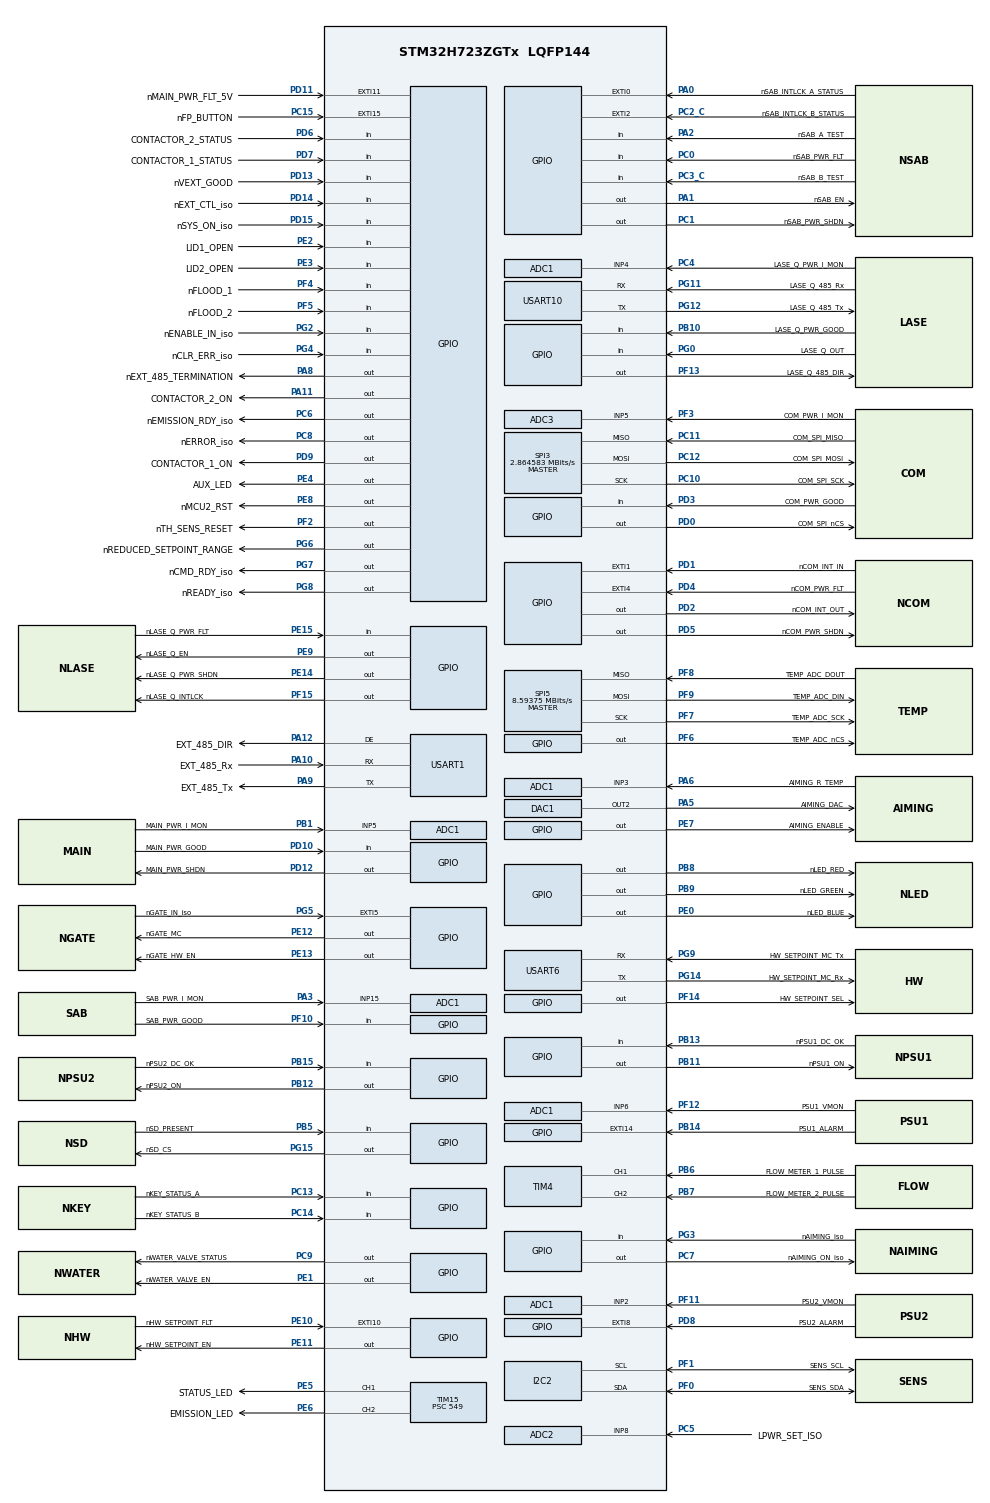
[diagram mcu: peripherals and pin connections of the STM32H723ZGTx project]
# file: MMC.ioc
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ADC1.Channel-0\#ChannelRegularConversion=ADC_CHANNEL_15
ADC1.ClockPrescaler=ADC_CLOCK_ASYNC_DIV2
ADC1.NbrOfConversionFlag=1
ADC1.OffsetNumber-0\#ChannelRegularConversion=ADC_OFFSET_NONE
ADC1.OffsetSignedSaturation-0\#ChannelRegularConversion=DISABLE
ADC1.Rank-0\#ChannelRegularConversion=1
ADC1.Resolution=ADC_RESOLUTION_12B
ADC1.SamplingTime-0\#ChannelRegularConversion=ADC_SAMPLETIME_1CYCLE_5
ADC1.master=1
ADC2.Channel-0\#ChannelRegularConversion=ADC_CHANNEL_8
ADC2.ClockPrescaler=ADC_CLOCK_ASYNC_DIV2
ADC2.NbrOfConversionFlag=1
ADC2.OffsetNumber-0\#ChannelRegularConversion=ADC_OFFSET_NONE
ADC2.OffsetSignedSaturation-0\#ChannelRegularConversion=DISABLE
ADC2.Rank-0\#ChannelRegularConversion=1
ADC2.SamplingTime-0\#ChannelRegularConversion=ADC_SAMPLETIME_1CYCLE_5
ADC2.ScanConvMode-ADC_Settings=ADC_SCAN_ENABLE
ADC3.Channel-0\#ChannelRegularConversion=ADC_CHANNEL_5
ADC3.ClockPrescaler=ADC_CLOCK_ASYNC_DIV2
ADC3.NbrOfConversionFlag=1
ADC3.OffsetNumber-0\#ChannelRegularConversion=ADC_OFFSET_NONE
ADC3.OffsetSign-0\#ChannelRegularConversion=ADC3_OFFSET_SIGN_NEGATIVE
ADC3.Rank-0\#ChannelRegularConversion=1
ADC3.SamplingTime-0\#ChannelRegularConversion=ADC3_SAMPLETIME_2CYCLES_5
CORTEX_M7.default_mode_Activation=1
DAC1.DAC_Channel-DAC_OUT2=DAC_CHANNEL_2
Dma.Request0=USART1_RX
Dma.Request1=USART1_TX
Dma.Request2=USART10_RX
Dma.Request3=USART10_TX
Dma.Request4=SPI3_RX
Dma.Request5=SPI3_TX
Dma.SPI3_RX.4.Direction=DMA_PERIPH_TO_MEMORY
Dma.SPI3_RX.4.EventEnable=DISABLE
Dma.SPI3_RX.4.FIFOMode=DMA_FIFOMODE_DISABLE
Dma.SPI3_RX.4.Instance=DMA1_Stream4
Dma.SPI3_RX.4.MemDataAlignment=DMA_MDATAALIGN_BYTE
Dma.SPI3_RX.4.MemInc=DMA_MINC_ENABLE
Dma.SPI3_RX.4.Mode=DMA_NORMAL
Dma.SPI3_RX.4.PeriphDataAlignment=DMA_PDATAALIGN_BYTE
Dma.SPI3_RX.4.PeriphInc=DMA_PINC_DISABLE
Dma.SPI3_RX.4.Polarity=HAL_DMAMUX_REQ_GEN_RISING
Dma.SPI3_RX.4.Priority=DMA_PRIORITY_LOW
Dma.SPI3_RX.4.RequestNumber=1
Dma.SPI3_RX.4.SignalID=NONE
Dma.SPI3_RX.4.SyncEnable=DISABLE
Dma.SPI3_RX.4.SyncPolarity=HAL_DMAMUX_SYNC_NO_EVENT
Dma.SPI3_RX.4.SyncRequestNumber=1
Dma.SPI3_RX.4.SyncSignalID=NONE
Dma.SPI3_TX.5.Direction=DMA_MEMORY_TO_PERIPH
Dma.SPI3_TX.5.EventEnable=DISABLE
Dma.SPI3_TX.5.FIFOMode=DMA_FIFOMODE_DISABLE
Dma.SPI3_TX.5.Instance=DMA1_Stream5
Dma.SPI3_TX.5.MemDataAlignment=DMA_MDATAALIGN_BYTE
Dma.SPI3_TX.5.MemInc=DMA_MINC_ENABLE
Dma.SPI3_TX.5.Mode=DMA_NORMAL
Dma.SPI3_TX.5.PeriphDataAlignment=DMA_PDATAALIGN_BYTE
Dma.SPI3_TX.5.PeriphInc=DMA_PINC_DISABLE
Dma.SPI3_TX.5.Polarity=HAL_DMAMUX_REQ_GEN_RISING
Dma.SPI3_TX.5.Priority=DMA_PRIORITY_LOW
Dma.SPI3_TX.5.RequestNumber=1
Dma.SPI3_TX.5.SignalID=NONE
Dma.SPI3_TX.5.SyncEnable=DISABLE
Dma.SPI3_TX.5.SyncPolarity=HAL_DMAMUX_SYNC_NO_EVENT
Dma.SPI3_TX.5.SyncRequestNumber=1
Dma.SPI3_TX.5.SyncSignalID=NONE
Dma.USART10_RX.2.Direction=DMA_PERIPH_TO_MEMORY
Dma.USART10_RX.2.EventEnable=DISABLE
Dma.USART10_RX.2.FIFOMode=DMA_FIFOMODE_DISABLE
Dma.USART10_RX.2.Instance=DMA1_Stream2
Dma.USART10_RX.2.MemDataAlignment=DMA_MDATAALIGN_BYTE
Dma.USART10_RX.2.MemInc=DMA_MINC_ENABLE
Dma.USART10_RX.2.Mode=DMA_NORMAL
Dma.USART10_RX.2.PeriphDataAlignment=DMA_PDATAALIGN_BYTE
Dma.USART10_RX.2.PeriphInc=DMA_PINC_DISABLE
Dma.USART10_RX.2.Polarity=HAL_DMAMUX_REQ_GEN_RISING
Dma.USART10_RX.2.Priority=DMA_PRIORITY_LOW
Dma.USART10_RX.2.RequestNumber=1
Dma.USART10_RX.2.SignalID=NONE
Dma.USART10_RX.2.SyncEnable=DISABLE
Dma.USART10_RX.2.SyncPolarity=HAL_DMAMUX_SYNC_NO_EVENT
Dma.USART10_RX.2.SyncRequestNumber=1
Dma.USART10_RX.2.SyncSignalID=NONE
Dma.USART10_TX.3.Direction=DMA_MEMORY_TO_PERIPH
Dma.USART10_TX.3.EventEnable=DISABLE
Dma.USART10_TX.3.FIFOMode=DMA_FIFOMODE_DISABLE
Dma.USART10_TX.3.Instance=DMA1_Stream3
Dma.USART10_TX.3.MemDataAlignment=DMA_MDATAALIGN_BYTE
Dma.USART10_TX.3.MemInc=DMA_MINC_ENABLE
Dma.USART10_TX.3.Mode=DMA_NORMAL
Dma.USART10_TX.3.PeriphDataAlignment=DMA_PDATAALIGN_BYTE
Dma.USART10_TX.3.PeriphInc=DMA_PINC_DISABLE
Dma.USART10_TX.3.Polarity=HAL_DMAMUX_REQ_GEN_RISING
Dma.USART10_TX.3.Priority=DMA_PRIORITY_LOW
Dma.USART10_TX.3.RequestNumber=1
Dma.USART10_TX.3.SignalID=NONE
Dma.USART10_TX.3.SyncEnable=DISABLE
Dma.USART10_TX.3.SyncPolarity=HAL_DMAMUX_SYNC_NO_EVENT
Dma.USART10_TX.3.SyncRequestNumber=1
Dma.USART10_TX.3.SyncSignalID=NONE
Dma.USART1_RX.0.Direction=DMA_PERIPH_TO_MEMORY
Dma.USART1_RX.0.EventEnable=DISABLE
Dma.USART1_RX.0.FIFOMode=DMA_FIFOMODE_DISABLE
Dma.USART1_RX.0.Instance=DMA1_Stream0
Dma.USART1_RX.0.MemDataAlignment=DMA_MDATAALIGN_BYTE
Dma.USART1_RX.0.MemInc=DMA_MINC_ENABLE
Dma.USART1_RX.0.Mode=DMA_CIRCULAR
Dma.USART1_RX.0.PeriphDataAlignment=DMA_PDATAALIGN_BYTE
Dma.USART1_RX.0.PeriphInc=DMA_PINC_DISABLE
Dma.USART1_RX.0.Polarity=HAL_DMAMUX_REQ_GEN_RISING
Dma.USART1_RX.0.Priority=DMA_PRIORITY_LOW
Dma.USART1_RX.0.RequestNumber=1
Dma.USART1_RX.0.SignalID=NONE
Dma.USART1_RX.0.SyncEnable=DISABLE
Dma.USART1_RX.0.SyncPolarity=HAL_DMAMUX_SYNC_NO_EVENT
Dma.USART1_RX.0.SyncRequestNumber=1
Dma.USART1_RX.0.SyncSignalID=NONE
Dma.USART1_TX.1.Direction=DMA_MEMORY_TO_PERIPH
Dma.USART1_TX.1.EventEnable=DISABLE
Dma.USART1_TX.1.FIFOMode=DMA_FIFOMODE_DISABLE
Dma.USART1_TX.1.Instance=DMA1_Stream1
Dma.USART1_TX.1.MemDataAlignment=DMA_MDATAALIGN_BYTE
Dma.USART1_TX.1.MemInc=DMA_MINC_ENABLE
Dma.USART1_TX.1.Mode=DMA_NORMAL
Dma.USART1_TX.1.PeriphDataAlignment=DMA_PDATAALIGN_BYTE
Dma.USART1_TX.1.PeriphInc=DMA_PINC_DISABLE
Dma.USART1_TX.1.Polarity=HAL_DMAMUX_REQ_GEN_RISING
Dma.USART1_TX.1.Priority=DMA_PRIORITY_LOW
Dma.USART1_TX.1.RequestNumber=1
Dma.USART1_TX.1.SignalID=NONE
Dma.USART1_TX.1.SyncEnable=DISABLE
Dma.USART1_TX.1.SyncPolarity=HAL_DMAMUX_SYNC_NO_EVENT
Dma.USART1_TX.1.SyncRequestNumber=1
Dma.USART1_TX.1.SyncSignalID=NONE
FREERTOS.Tasks01=defaultTask,24,256,StartDefaultTask,Default,NULL,Dynamic,NULL,NULL
FREERTOS.configMINIMAL_STACK_SIZE=256
FREERTOS.configUSE_NEWLIB_REENTRANT=1
I2C2.I2C_Fall_Time=10
I2C2.I2C_Rise_Time=0
I2C2.Timing=0x308087CA
IWDG1.Prescaler=IWDG_PRESCALER_256
Mcu.Family=STM32H7
Mcu.Name=STM32H723ZGTx
Mcu.Package=LQFP144
NVIC.DMA1_Stream0_IRQn=true\:5\:0\:false\:false\:true\:true\:false\:true\:true
NVIC.DMA1_Stream1_IRQn=true\:5\:0\:false\:false\:true\:true\:false\:true\:true
NVIC.DMA1_Stream2_IRQn=true\:5\:0\:false\:false\:true\:true\:false\:true\:true
NVIC.DMA1_Stream3_IRQn=true\:5\:0\:false\:false\:true\:true\:false\:true\:true
NVIC.DMA1_Stream4_IRQn=true\:5\:0\:false\:false\:true\:true\:false\:true\:true
NVIC.DMA1_Stream5_IRQn=true\:5\:0\:false\:false\:true\:true\:false\:true\:true
NVIC.EXTI0_IRQn=true\:5\:0\:false\:false\:true\:true\:true\:true\:true
NVIC.EXTI15_10_IRQn=true\:5\:0\:false\:false\:true\:true\:true\:true\:true
NVIC.EXTI1_IRQn=true\:5\:0\:false\:false\:true\:true\:true\:true\:true
NVIC.EXTI2_IRQn=true\:5\:0\:false\:false\:true\:true\:true\:true\:true
NVIC.EXTI4_IRQn=true\:5\:0\:false\:false\:true\:true\:true\:true\:true
NVIC.EXTI9_5_IRQn=true\:5\:0\:false\:false\:true\:true\:true\:true\:true
NVIC.I2C2_ER_IRQn=true\:5\:0\:false\:false\:true\:true\:true\:true\:true
NVIC.I2C2_EV_IRQn=true\:5\:0\:false\:false\:true\:true\:true\:true\:true
NVIC.PriorityGroup=NVIC_PRIORITYGROUP_4
NVIC.SPI3_IRQn=true\:5\:0\:false\:false\:true\:true\:false\:true\:true
NVIC.SPI5_IRQn=true\:5\:0\:false\:false\:true\:true\:true\:true\:true
NVIC.TIM16_IRQn=true\:5\:0\:false\:false\:true\:true\:true\:true\:true
NVIC.TIM1_UP_IRQn=true\:15\:0\:false\:false\:true\:false\:false\:true\:true
NVIC.TIM4_IRQn=true\:5\:0\:false\:false\:true\:true\:true\:true\:true
NVIC.TimeBase=TIM1_UP_IRQn
NVIC.TimeBaseIP=TIM1
NVIC.USART10_IRQn=true\:5\:0\:false\:false\:true\:true\:true\:true\:true
NVIC.USART1_IRQn=true\:5\:0\:true\:false\:true\:true\:true\:true\:true
NVIC.USART6_IRQn=true\:5\:0\:false\:false\:true\:true\:true\:true\:true
PA0.GPIO_Label=nSAB_INTLCK_A_STATUS
PA0.GPIO_ModeDefaultEXTI=GPIO_MODE_IT_RISING_FALLING
PA0.Signal=GPXTI0
PA1.GPIO_Label=nSAB_EN
PA1.PinState=GPIO_PIN_SET
PA1.Signal=GPIO_Output
PA10.GPIO_Label=EXT_485_Rx
PA10.Mode=Asynchronous
PA10.Signal=USART1_RX
PA11.GPIO_Label=CONTACTOR_2_ON
PA11.Signal=GPIO_Output
PA12.GPIO_Label=EXT_485_DIR
PA12.Mode=Hardware Flow Control (RS485)
PA12.Signal=USART1_DE
PA13(JTMS/SWDIO).Mode=JTAG_5_pins
PA13(JTMS/SWDIO).Signal=DEBUG_JTMS-SWDIO
PA14(JTCK/SWCLK).Mode=JTAG_5_pins
PA14(JTCK/SWCLK).Signal=DEBUG_JTCK-SWCLK
PA15(JTDI).Mode=JTAG_5_pins
PA15(JTDI).Signal=DEBUG_JTDI
PA2.GPIO_Label=nSAB_A_TEST
PA2.Signal=GPIO_Input
PA3.GPIO_Label=SAB_PWR_I_MON
PA3.Signal=ADCx_INP15
PA5.GPIO_Label=AIMING_DAC
PA5.Signal=COMP_DAC12_group
PA6.GPIO_Label=AIMING_R_TEMP
PA6.Signal=ADCx_INP3
PA8.GPIO_Label=nEXT_485_TERMINATION
PA8.PinState=GPIO_PIN_RESET
PA8.Signal=GPIO_Output
PA9.GPIO_Label=EXT_485_Tx
PA9.Mode=Asynchronous
PA9.Signal=USART1_TX
PB1.GPIO_Label=MAIN_PWR_I_MON
PB1.Signal=ADCx_INP5
PB10.GPIO_Label=LASE_Q_PWR_GOOD
PB10.Signal=GPIO_Input
PB11.GPIO_Label=nPSU1_ON
PB11.PinState=GPIO_PIN_SET
PB11.Signal=GPIO_Output
PB12.GPIO_Label=nPSU2_ON
PB12.PinState=GPIO_PIN_SET
PB12.Signal=GPIO_Output
PB13.GPIO_Label=nPSU1_DC_OK
PB13.Signal=GPIO_Input
PB14.GPIO_Label=PSU1_ALARM
PB14.GPIO_ModeDefaultEXTI=GPIO_MODE_IT_RISING_FALLING
PB14.Signal=GPXTI14
PB15.GPIO_Label=nPSU2_DC_OK
PB15.Signal=GPIO_Input
PB3(JTDO/TRACESWO).Mode=JTAG_5_pins
PB3(JTDO/TRACESWO).Signal=DEBUG_JTDO-SWO
PB4(NJTRST).Mode=JTAG_5_pins
PB4(NJTRST).Signal=DEBUG_JTRST
PB5.GPIO_Label=nSD_PRESENT
PB5.Signal=GPIO_Input
PB6.GPIO_Label=FLOW_METER_1_PULSE
PB6.Signal=S_TIM4_CH1
PB7.GPIO_Label=FLOW_METER_2_PULSE
PB7.Signal=S_TIM4_CH2
PB8.GPIO_Label=nLED_RED
PB8.PinState=GPIO_PIN_SET
PB8.Signal=GPIO_Output
PB9.GPIO_Label=nLED_GREEN
PB9.PinState=GPIO_PIN_SET
PB9.Signal=GPIO_Output
PC0.GPIO_Label=nSAB_PWR_FLT
PC0.Signal=GPIO_Input
PC1.GPIO_Label=nSAB_PWR_SHDN
PC1.Signal=GPIO_Output
PC10.GPIO_Label=COM_SPI_SCK
PC10.GPIO_PuPd=GPIO_PULLDOWN
PC10.Mode=Full_Duplex_Master
PC10.Signal=SPI3_SCK
PC11.GPIO_Label=COM_SPI_MISO
PC11.Mode=Full_Duplex_Master
PC11.Signal=SPI3_MISO
PC12.GPIO_Label=COM_SPI_MOSI
PC12.Mode=Full_Duplex_Master
PC12.Signal=SPI3_MOSI
PC13.GPIO_Label=nKEY_STATUS_A
PC13.Signal=GPIO_Input
PC14-OSC32_IN.GPIO_Label=nKEY_STATUS_B
PC14-OSC32_IN.Signal=GPIO_Input
PC15-OSC32_OUT.GPIO_Label=nFP_BUTTON
PC15-OSC32_OUT.GPIO_ModeDefaultEXTI=GPIO_MODE_IT_RISING_FALLING
PC15-OSC32_OUT.Signal=GPXTI15
PC2_C.GPIO_Label=nSAB_INTLCK_B_STATUS
PC2_C.GPIO_ModeDefaultEXTI=GPIO_MODE_IT_RISING_FALLING
PC2_C.Signal=GPXTI2
PC3_C.GPIO_Label=nSAB_B_TEST
PC3_C.Signal=GPIO_Input
PC4.GPIO_Label=LASE_Q_PWR_I_MON
PC4.Signal=ADCx_INP4
PC5.GPIO_Label=LPWR_SET_ISO
PC5.Signal=ADCx_INP8
PC6.GPIO_Label=nEMISSION_RDY_iso
PC6.PinState=GPIO_PIN_SET
PC6.Signal=GPIO_Output
PC7.GPIO_Label=nAIMING_ON_iso
PC7.PinState=GPIO_PIN_SET
PC7.Signal=GPIO_Output
PC8.GPIO_Label=nERROR_iso
PC8.PinState=GPIO_PIN_SET
PC8.Signal=GPIO_Output
PC9.GPIO_Label=nWATER_VALVE_STATUS
PC9.PinState=GPIO_PIN_SET
PC9.Signal=GPIO_Output
PD0.GPIO_Label=COM_SPI_nCS
PD0.PinState=GPIO_PIN_SET
PD0.Signal=GPIO_Output
PD1.GPIO_Label=nCOM_INT_IN
PD1.GPIO_ModeDefaultEXTI=GPIO_MODE_IT_FALLING
PD1.Signal=GPXTI1
PD10.GPIO_Label=MAIN_PWR_GOOD
PD10.Signal=GPIO_Input
PD11.GPIO_Label=nMAIN_PWR_FLT_5V
PD11.Signal=GPXTI11
PD12.GPIO_Label=MAIN_PWR_SHDN
PD12.Signal=GPIO_Output
PD13.GPIO_Label=nVEXT_GOOD
PD13.Signal=GPIO_Input
PD14.GPIO_Label=nEXT_CTL_iso
PD14.Signal=GPIO_Input
PD15.GPIO_Label=nSYS_ON_iso
PD15.Signal=GPIO_Input
PD2.GPIO_Label=nCOM_INT_OUT
PD2.PinState=GPIO_PIN_SET
PD2.Signal=GPIO_Output
PD3.GPIO_Label=COM_PWR_GOOD
PD3.Signal=GPIO_Input
PD4.GPIO_Label=nCOM_PWR_FLT
PD4.Signal=GPXTI4
PD5.GPIO_Label=nCOM_PWR_SHDN
PD5.Signal=GPIO_Output
PD6.GPIO_Label=CONTACTOR_2_STATUS
PD6.Signal=GPIO_Input
PD7.GPIO_Label=CONTACTOR_1_STATUS
PD7.Signal=GPIO_Input
PD8.GPIO_Label=PSU2_ALARM
PD8.GPIO_ModeDefaultEXTI=GPIO_MODE_IT_RISING_FALLING
PD8.Signal=GPXTI8
PD9.GPIO_Label=CONTACTOR_1_ON
PD9.Signal=GPIO_Output
PE0.GPIO_Label=nLED_BLUE
PE0.PinState=GPIO_PIN_SET
PE0.Signal=GPIO_Output
PE1.GPIO_Label=nWATER_VALVE_EN
PE1.PinState=GPIO_PIN_SET
PE1.Signal=GPIO_Output
PE10.GPIO_Label=nHW_SETPOINT_FLT
PE10.Signal=GPXTI10
PE11.GPIO_Label=nHW_SETPOINT_EN
PE11.PinState=GPIO_PIN_SET
PE11.Signal=GPIO_Output
PE12.GPIO_Label=nGATE_MC
PE12.PinState=GPIO_PIN_SET
PE12.Signal=GPIO_Output
PE13.GPIO_Label=nGATE_HW_EN
PE13.PinState=GPIO_PIN_SET
PE13.Signal=GPIO_Output
PE14.GPIO_Label=nLASE_Q_PWR_SHDN
PE14.Signal=GPIO_Output
PE15.GPIO_Label=nLASE_Q_PWR_FLT
PE15.Signal=GPIO_Input
PE2.GPIO_Label=LID1_OPEN
PE2.Signal=GPIO_Input
PE3.GPIO_Label=LID2_OPEN
PE3.Signal=GPIO_Input
PE4.GPIO_Label=AUX_LED
PE4.Signal=GPIO_Output
PE5.GPIO_Label=STATUS_LED
PE5.Signal=S_TIM15_CH1
PE6.GPIO_Label=EMISSION_LED
PE6.Signal=S_TIM15_CH2
PE7.GPIO_Label=AIMING_ENABLE
PE7.Signal=GPIO_Output
PE8.GPIO_Label=nMCU2_RST
PE8.GPIO_ModeDefaultOutputPP=GPIO_MODE_OUTPUT_OD
PE8.GPIO_PuPd=GPIO_NOPULL
PE8.PinState=GPIO_PIN_SET
PE8.Signal=GPIO_Output
PE9.GPIO_Label=nLASE_Q_EN
PE9.PinState=GPIO_PIN_SET
PE9.Signal=GPIO_Output
PF0.GPIO_Label=SENS_SDA
PF0.Mode=I2C
PF0.Signal=I2C2_SDA
PF1.GPIO_Label=SENS_SCL
PF1.Mode=I2C
PF1.Signal=I2C2_SCL
PF10.GPIO_Label=SAB_PWR_GOOD
PF10.Signal=GPIO_Input
PF11.GPIO_Label=PSU2_VMON
PF11.Mode=IN2-Single-Ended
PF11.Signal=ADC1_INP2
PF12.GPIO_Label=PSU1_VMON
PF12.Mode=IN6-Single-Ended
PF12.Signal=ADC1_INP6
PF13.GPIO_Label=LASE_Q_485_DIR
PF13.Signal=GPIO_Output
PF14.GPIO_Label=HW_SETPOINT_SEL
PF14.Signal=GPIO_Output
PF15.GPIO_Label=nLASE_Q_INTLCK
PF15.PinState=GPIO_PIN_SET
PF15.Signal=GPIO_Output
PF2.GPIO_Label=nTH_SENS_RESET
PF2.Signal=GPIO_Output
PF3.GPIO_Label=COM_PWR_I_MON
PF3.Mode=IN5-Single-Ended
PF3.Signal=ADC3_INP5
PF4.GPIO_Label=nFLOOD_1
PF4.Signal=GPIO_Input
PF5.GPIO_Label=nFLOOD_2
PF5.Signal=GPIO_Input
PF6.GPIO_Label=TEMP_ADC_nCS
PF6.PinState=GPIO_PIN_SET
PF6.Signal=GPIO_Output
PF7.GPIO_Label=TEMP_ADC_SCK
PF7.Mode=Full_Duplex_Master
PF7.Signal=SPI5_SCK
PF8.GPIO_Label=TEMP_ADC_DOUT
PF8.Mode=Full_Duplex_Master
PF8.Signal=SPI5_MISO
PF9.GPIO_Label=TEMP_ADC_DIN
PF9.Mode=Full_Duplex_Master
PF9.Signal=SPI5_MOSI
PG0.GPIO_Label=LASE_Q_OUT
PG0.Signal=GPIO_Input
PG11.GPIO_Label=LASE_Q_485_Rx
PG11.Mode=Asynchronous
PG11.Signal=USART10_RX
PG12.GPIO_Label=LASE_Q_485_Tx
PG12.Mode=Asynchronous
PG12.Signal=USART10_TX
PG14.GPIO_Label=HW_SETPOINT_MC_Rx
PG14.Mode=Asynchronous
PG14.Signal=USART6_TX
PG15.GPIO_Label=nSD_CS
PG15.PinState=GPIO_PIN_SET
PG15.Signal=GPIO_Output
PG2.GPIO_Label=nENABLE_IN_iso
PG2.Signal=GPIO_Input
PG3.GPIO_Label=nAIMING_iso
PG3.Signal=GPIO_Input
PG4.GPIO_Label=nCLR_ERR_iso
PG4.Signal=GPIO_Input
PG5.GPIO_Label=nGATE_IN_iso
PG5.Signal=GPXTI5
PG6.GPIO_Label=nREDUCED_SETPOINT_RANGE
PG6.PinState=GPIO_PIN_SET
PG6.Signal=GPIO_Output
PG7.GPIO_Label=nCMD_RDY_iso
PG7.PinState=GPIO_PIN_SET
PG7.Signal=GPIO_Output
PG8.GPIO_Label=nREADY_iso
PG8.PinState=GPIO_PIN_SET
PG8.Signal=GPIO_Output
PG9.GPIO_Label=HW_SETPOINT_MC_Tx
PG9.Mode=Asynchronous
PG9.Signal=USART6_RX
PH0-OSC_IN.Mode=HSE-External-Oscillator
PH0-OSC_IN.Signal=RCC_OSC_IN
PH1-OSC_OUT.Mode=HSE-External-Oscillator
PH1-OSC_OUT.Signal=RCC_OSC_OUT
ProjectManager.HeapSize=0x200
ProjectManager.StackSize=0x400
ProjectManager.TargetToolchain=STM32CubeIDE
RCC.ADCCLockSelection=RCC_ADCCLKSOURCE_CLKP
RCC.ADCFreq_Value=64000000
RCC.APB1Freq_Value=137500000
RCC.APB2Freq_Value=137500000
RCC.APB3Freq_Value=137500000
RCC.APB4Freq_Value=137500000
RCC.CortexFreq_Value=550000000
RCC.D1PPRE=RCC_APB3_DIV2
RCC.D2PPRE1=RCC_APB1_DIV2
RCC.D2PPRE2=RCC_APB2_DIV2
RCC.D3PPRE=RCC_APB4_DIV2
RCC.DIVM1=2
RCC.DIVM2=2
RCC.DIVN1=44
RCC.DIVN2=32
RCC.DIVP1=1
RCC.DIVQ1=3
RCC.HCLKFreq_Value=275000000
RCC.HPRE=RCC_HCLK_DIV2
RCC.PLL2FRACN=0
RCC.PLL3FRACN=0
RCC.PLL3_VCI_Range-AdvancedSettings=RCC_PLL3VCIRANGE_3
RCC.PLL3_VCO_SEL-AdvancedSettings=RCC_PLL3VCOWIDE
RCC.PLLFRACN=0
RCC.PLLSourceVirtual=RCC_PLLSOURCE_HSE
RCC.SYSCLKFreq_VALUE=550000000
RCC.SYSCLKSource=RCC_SYSCLKSOURCE_PLLCLK
RCC.USBFreq_Value=183333333.33333334
SH.ADCx_INP15.0=ADC1_INP15,IN15-Single-Ended
SH.ADCx_INP3.0=ADC1_INP3,IN3-Single-Ended
SH.ADCx_INP4.0=ADC1_INP4,IN4-Single-Ended
SH.ADCx_INP5.0=ADC1_INP5,IN5-Single-Ended
SH.ADCx_INP8.0=ADC2_INP8,IN8-Single-Ended
SH.COMP_DAC12_group.0=DAC1_OUT2,DAC_OUT2
SH.S_TIM15_CH1.0=TIM15_CH1,PWM Generation1 CH1
SH.S_TIM15_CH2.0=TIM15_CH2,PWM Generation2 CH2
SH.S_TIM4_CH1.0=TIM4_CH1,Input_Capture1_from_TI1
SH.S_TIM4_CH2.0=TIM4_CH2,Input_Capture2_from_TI2
SPI3.BaudRatePrescaler=SPI_BAUDRATEPRESCALER_64
SPI3.CalculateBaudRate=2.864583 MBits/s
SPI3.DataSize=SPI_DATASIZE_8BIT
SPI3.Direction=SPI_DIRECTION_2LINES
SPI3.Mode=SPI_MODE_MASTER
SPI3.VirtualType=VM_MASTER
SPI5.BaudRatePrescaler=SPI_BAUDRATEPRESCALER_16
SPI5.CLKPhase=SPI_PHASE_2EDGE
SPI5.CalculateBaudRate=8.59375 MBits/s
SPI5.DataSize=SPI_DATASIZE_8BIT
SPI5.Direction=SPI_DIRECTION_2LINES
SPI5.Mode=SPI_MODE_MASTER
SPI5.VirtualType=VM_MASTER
TIM15.Channel-PWM\ Generation1\ CH1=TIM_CHANNEL_1
TIM15.Channel-PWM\ Generation2\ CH2=TIM_CHANNEL_2
TIM15.Period=999
TIM15.Prescaler=549
TIM4.Channel-Input_Capture1_from_TI1=TIM_CHANNEL_1
TIM4.Channel-Input_Capture2_from_TI2=TIM_CHANNEL_2
USART1.VirtualMode-Asynchronous=VM_ASYNC
USART1.VirtualMode-Hardware\ Flow\ Control\ (RS485)=VM_ASYNC
USART10.VirtualMode-Asynchronous=VM_ASYNC
USART6.VirtualMode-Asynchronous=VM_ASYNC
VP_CRC_VS_CRC.Mode=CRC_Activate
VP_FATFS_VS_Generic.Mode=User_defined
VP_FREERTOS_VS_CMSIS_V2.Mode=CMSIS_V2
VP_IWDG1_VS_IWDG.Mode=IWDG_Activate
VP_MEMORYMAP_VS_MEMORYMAP.Mode=CurAppReg
VP_RTC_VS_RTC_Activate.Mode=RTC_Enabled
VP_SYS_VS_tim1.Mode=TIM1
VP_TIM15_VS_ClockSourceINT.Mode=Internal
VP_TIM16_VS_ClockSourceINT.Mode=Enable_Timer
VP_TIM4_VS_ClockSourceINT.Mode=Internal
board=custom

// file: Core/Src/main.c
/* USER CODE BEGIN Header */
/**
  ******************************************************************************
  * @file           : main.c
  * @brief          : Main program body
  ******************************************************************************
  * @attention
  *
  * Copyright (c) 2026 STMicroelectronics.
  * All rights reserved.
  *
  * This software is licensed under terms that can be found in the LICENSE file
  * in the root directory of this software component.
  * If no LICENSE file comes with this software, it is provided AS-IS.
  *
  ******************************************************************************
  */
/* USER CODE END Header */
#include "main.h"
#include "FreeRTOS.h"
#include "cmsis_os2.h"
#include "fatfs.h"

/* USER CODE BEGIN Includes */
#include "config.h"
#include "lut_manager.h"
#include "Ext_interface.h"
#include "FlowMeter.h"
#include "LaseQ.h"
#include "LED.h"
#include "PSU.h"
#include "task_comms.h"
#include "Watchdog.h"
#include "QCW.h"
/* USER CODE END Includes */

ADC_HandleTypeDef hadc1;
ADC_HandleTypeDef hadc2;
ADC_HandleTypeDef hadc3;

CRC_HandleTypeDef hcrc;

DAC_HandleTypeDef hdac1;

I2C_HandleTypeDef hi2c2;

IWDG_HandleTypeDef hiwdg1;

RTC_HandleTypeDef hrtc;

SPI_HandleTypeDef hspi3;
SPI_HandleTypeDef hspi5;
DMA_HandleTypeDef hdma_spi3_rx;
DMA_HandleTypeDef hdma_spi3_tx;

TIM_HandleTypeDef htim4;
TIM_HandleTypeDef htim15;
TIM_HandleTypeDef htim16;

UART_HandleTypeDef huart1;
UART_HandleTypeDef huart6;
UART_HandleTypeDef huart10;
DMA_HandleTypeDef hdma_usart1_rx;
DMA_HandleTypeDef hdma_usart1_tx;
DMA_HandleTypeDef hdma_usart10_rx;
DMA_HandleTypeDef hdma_usart10_tx;

/* Definitions for defaultTask */
osThreadId_t defaultTaskHandle;
const osThreadAttr_t defaultTask_attributes = {
  .name = "defaultTask",
  .stack_size = 256 * 4,
  .priority = (osPriority_t) osPriorityNormal,
};

void SystemClock_Config(void);
void PeriphCommonClock_Config(void);
static void MPU_Config(void);
static void MX_GPIO_Init(void);
static void MX_DMA_Init(void);
static void MX_ADC1_Init(void);
static void MX_ADC2_Init(void);
static void MX_DAC1_Init(void);
static void MX_ADC3_Init(void);
static void MX_I2C2_Init(void);
static void MX_SPI3_Init(void);
static void MX_SPI5_Init(void);
static void MX_TIM4_Init(void);
static void MX_TIM15_Init(void);
static void MX_USART1_UART_Init(void);
static void MX_USART6_UART_Init(void);
static void MX_USART10_UART_Init(void);
static void MX_CRC_Init(void);
static void MX_RTC_Init(void);
static void MX_IWDG1_Init(void);
static void MX_TIM16_Init(void);
void StartDefaultTask(void *argument);

/* USER CODE BEGIN PFP */
extern void MX_FREERTOS_Init(void);  /* definita in freertos.c */
/* USER CODE END PFP */

int main(void)
{

  /* USER CODE BEGIN 1 */

  /*
   * FIX (2026-07-30): questo progetto ha DUE build separate (Slot A,
   * 0x08040000, e Slot B, 0x08080000 - vedi STM32H723ZGTX_FLASH.ld /
   * _SlotB.ld, §14.2 dell'analisi) - un indirizzo VTOR fisso qui sarebbe
   * sbagliato per la build Slot B. Quando parte tramite il bootloader, e'
   * Ota_JumpToApp() (MMC_Bootloader/App/OTA/ota_jump.c) a impostare
   * SCB->VTOR sull'indirizzo corretto PRIMA di cedere il controllo. Se pero'
   * questo progetto viene flashato/debuggato DA SOLO (bypassando il
   * bootloader, es. "Debug"/"Run" diretto da CubeIDE), VTOR resta al valore
   * di default (0x08000000, dominio del bootloader) - il primo interrupt che
   * scatta (tipicamente SysTick, usato internamente da HAL_GetTick()/
   * HAL_Delay() e dai timeout di HAL_RCC_OscConfig() dentro
   * SystemClock_Config()) legge il vettore dal punto sbagliato e salta dentro
   * codice/dati che non appartengono a questo progetto - osservato in banco
   * come un "break" senza informazioni di debug dentro SystemClock_Config(),
   * a un indirizzo ricadente nel settore del bootloader.
   * Fix: usare l'indirizzo del vector table stesso (g_pfnVectors, simbolo
   * definito in Core/Startup/startup_stm32h723zgtx.s) invece di un valore
   * fisso - il linker lo piazza sempre all'inizio della FLASH per QUALUNQUE
   * link (Slot A o Slot B), quindi risulta automaticamente corretto per
   * entrambe le build senza doverle distinguere qui. Impostato il prima
   * possibile (prima di HAL_Init(), che avvia il SysTick) - ridondante ma
   * innocuo quando si arriva dal bootloader (stesso valore), necessario per
   * poter debuggare/eseguire questo progetto anche da solo.
   */
  extern uint32_t g_pfnVectors[];
  SCB->VTOR = (uint32_t)g_pfnVectors;

  /*
   * FIX (2026-07-02): I/D-Cache non venivano MAI abilitate in questo progetto
   * (SCB_EnableICache()/SCB_EnableDCache() assenti ovunque — verificato via
   * grep sull'intero repo). Il D-Cache restava quindi disabilitato (nessun
   * dato realmente cachato, coerente col fatto che i tanti
   * SCB_InvalidateDCache_by_Addr() sparsi nei driver — AD7490, RS485,
   * config.c/lut_manager.c — sembravano "funzionare" senza effetto reale).
   *
   * PROBLEMA: sul Cortex-M7, le operazioni di manutenzione cache (Invalidate/
   * Clean by address) vengono eseguite dall'hardware ANCHE se il cache non è
   * mai stato abilitato — e in quel caso operano su tag-RAM del cache MAI
   * inizializzata (contenuto indefinito dopo il reset). Questo può generare
   * un BusFault hardware reale (problema documentato e noto sulla community
   * ST, non specifico di questo progetto). È la causa identificata
   * dell'HardFault riproducibile in Config_Save() -> SCB_InvalidateDCache_by_Addr()
   * durante l'indagine sul comando RS485 "SET TERM ON": l'indirizzo/size
   * passati alla chiamata sono sempre stati corretti (verificato in debug),
   * il fault dipendeva dallo stato non inizializzato del cache stesso.
   *
   * FIX: abilitare I/D-Cache qui, il più presto possibile in main() (prima
   * di MPU_Config()/HAL_Init(), come da prassi standard ST). Abilitare il
   * cache esegue un invalidate-all interno che porta la tag-RAM in uno stato
   * noto PRIMA che qualunque SCB_InvalidateDCache_by_Addr() venga chiamato.
   * Beneficio collaterale: i driver che già chiamavano queste funzioni ora
   * ottengono la coerenza cache che presumevano di avere fin dall'inizio.
   */
  SCB_EnableICache();
  SCB_EnableDCache();

  /* USER CODE END 1 */

  /* MPU Configuration--------------------------------------------------------*/
  MPU_Config();

  /* MCU Configuration--------------------------------------------------------*/

  /* Reset of all peripherals, Initializes the Flash interface and the Systick. */
  HAL_Init();

  /* Configure the system clock */
  SystemClock_Config();

  /* Configure the peripherals common clocks */
  PeriphCommonClock_Config();

  /* Initialize all configured peripherals */
  MX_GPIO_Init();
  MX_DMA_Init();
  MX_ADC1_Init();
  MX_ADC2_Init();
  MX_DAC1_Init();
  MX_ADC3_Init();
  MX_I2C2_Init();
  MX_SPI3_Init();
  MX_SPI5_Init();
  MX_TIM4_Init();
  MX_TIM15_Init();
  MX_USART1_UART_Init();
  MX_USART6_UART_Init();
  MX_USART10_UART_Init();
  MX_CRC_Init();
  MX_RTC_Init();
  MX_FATFS_Init();
  MX_IWDG1_Init();
  MX_TIM16_Init();
  /* USER CODE BEGIN 2 */
  /* ========================================================================== */
  /*--- Load configuration---*/
  /* ========================================================================== */
  //Inizializzazione del modulo di configurazione e caricamento configurazione
  Config_Init(&hcrc);

  /*
   * BUG STORICO (osservato 2026-07-27): LUT_Init() non veniva MAI chiamata
   * in tutto il firmware. lut_manager.c scrive/legge correttamente da/verso
   * flash (SAVE LUT persisteva davvero le entry, come confermato da GET LUT
   * VCOMP subito dopo il salvataggio), ma senza questa chiamata s_lut resta
   * la sua inizializzazione statica (BSS, tutta a zero: voltage_comp_size=0)
   * per l'intera vita del firmware — la LUT persistita in flash non veniva
   * MAI ricaricata in RAM al boot. Sintomo: "SAVE LUT" risponde OK e "GET
   * LUT VCOMP" la mostra corretta finché non si riavvia, poi torna a 0/10
   * entry ad ogni power-cycle, a prescindere da quante volte la si sia
   * salvata. Va chiamata qui, subito dopo Config_Init() (stesso settore
   * flash, stessa fase pre-RTOS: Config_FlashMutexAcquire() ritorna sempre
   * true quando il mutex non esiste ancora, vedi config.c) e PRIMA di
   * qualunque modulo che consumi le LUT (AMC_Init(), inizializzato in
   * MX_FREERTOS_Init() sotto).
   */
  LUT_Init();

  /* ========================================================================== */
  /*--- Hardware initialization (See Drivers section) ---*/
  /* ========================================================================== */

  //Ext interface
  EXT_Interface_Init(&hadc2,g_config.reduced_setpoint_range);
  //Flussometri
  FlowMeter_Init(FLOW_METER_1,&htim4, TIM_CHANNEL_1);
  //FlowMeter_Init(FLOW_METER_2,&htim4, TIM_CHANNEL_2);
  //Lase Q
 	//Lase Q inizializzato in TaskComms_Init()
  //Front panel LEDs
  FPLED_Init(&htim15);
  //PSU
  PSUInit(PSU1);
  //PSUInit(PSU2);

  /* USER CODE END 2 */

  /* Init scheduler */
  osKernelInitialize();

  /* Create the thread(s) */
  /* creation of defaultTask */
  defaultTaskHandle = osThreadNew(StartDefaultTask, NULL, &defaultTask_attributes);

  /* USER CODE BEGIN RTOS_THREADS */
  MX_FREERTOS_Init();  /* crea tutti i task applicativi (Monitor, FSM, Comms, ...) */
  /* USER CODE END RTOS_THREADS */

  /* Start scheduler */
  osKernelStart();

  /* We should never get here as control is now taken by the scheduler */

  /* Infinite loop */
  while (1)
  {

  }
}

void SystemClock_Config(void)
{
  RCC_OscInitTypeDef RCC_OscInitStruct = {0};
  RCC_ClkInitTypeDef RCC_ClkInitStruct = {0};

  /** Supply configuration update enable
  */
  HAL_PWREx_ConfigSupply(PWR_LDO_SUPPLY);

  /** Configure the main internal regulator output voltage
  */
  __HAL_PWR_VOLTAGESCALING_CONFIG(PWR_REGULATOR_VOLTAGE_SCALE0);

  while(!__HAL_PWR_GET_FLAG(PWR_FLAG_VOSRDY)) {}

  /** Initializes the RCC Oscillators according to the specified parameters
  * in the RCC_OscInitTypeDef structure.
  */
  RCC_OscInitStruct.OscillatorType = RCC_OSCILLATORTYPE_HSI|RCC_OSCILLATORTYPE_LSI
                              |RCC_OSCILLATORTYPE_HSE;
  RCC_OscInitStruct.HSEState = RCC_HSE_ON;
  RCC_OscInitStruct.HSIState = RCC_HSI_DIV1;
  RCC_OscInitStruct.HSICalibrationValue = 64;
  RCC_OscInitStruct.LSIState = RCC_LSI_ON;
  RCC_OscInitStruct.PLL.PLLState = RCC_PLL_ON;
  RCC_OscInitStruct.PLL.PLLSource = RCC_PLLSOURCE_HSE;
  RCC_OscInitStruct.PLL.PLLM = 2;
  RCC_OscInitStruct.PLL.PLLN = 44;
  RCC_OscInitStruct.PLL.PLLP = 1;
  RCC_OscInitStruct.PLL.PLLQ = 3;
  RCC_OscInitStruct.PLL.PLLR = 2;
  RCC_OscInitStruct.PLL.PLLRGE = RCC_PLL1VCIRANGE_3;
  RCC_OscInitStruct.PLL.PLLVCOSEL = RCC_PLL1VCOWIDE;
  RCC_OscInitStruct.PLL.PLLFRACN = 0;
  if (HAL_RCC_OscConfig(&RCC_OscInitStruct) != HAL_OK)
  {
    Error_Handler();
  }

  /** Initializes the CPU, AHB and APB buses clocks
  */
  RCC_ClkInitStruct.ClockType = RCC_CLOCKTYPE_HCLK|RCC_CLOCKTYPE_SYSCLK
                              |RCC_CLOCKTYPE_PCLK1|RCC_CLOCKTYPE_PCLK2
                              |RCC_CLOCKTYPE_D3PCLK1|RCC_CLOCKTYPE_D1PCLK1;
  RCC_ClkInitStruct.SYSCLKSource = RCC_SYSCLKSOURCE_PLLCLK;
  RCC_ClkInitStruct.SYSCLKDivider = RCC_SYSCLK_DIV1;
  RCC_ClkInitStruct.AHBCLKDivider = RCC_HCLK_DIV2;
  RCC_ClkInitStruct.APB3CLKDivider = RCC_APB3_DIV2;
  RCC_ClkInitStruct.APB1CLKDivider = RCC_APB1_DIV2;
  RCC_ClkInitStruct.APB2CLKDivider = RCC_APB2_DIV2;
  RCC_ClkInitStruct.APB4CLKDivider = RCC_APB4_DIV2;

  if (HAL_RCC_ClockConfig(&RCC_ClkInitStruct, FLASH_LATENCY_3) != HAL_OK)
  {
    Error_Handler();
  }
}

void PeriphCommonClock_Config(void)
{
  RCC_PeriphCLKInitTypeDef PeriphClkInitStruct = {0};

  /** Initializes the peripherals clock
  */
  PeriphClkInitStruct.PeriphClockSelection = RCC_PERIPHCLK_CKPER;
  PeriphClkInitStruct.CkperClockSelection = RCC_CLKPSOURCE_HSI;
  if (HAL_RCCEx_PeriphCLKConfig(&PeriphClkInitStruct) != HAL_OK)
  {
    Error_Handler();
  }
}

static void MX_ADC1_Init(void)
{

  ADC_MultiModeTypeDef multimode = {0};
  ADC_ChannelConfTypeDef sConfig = {0};

  /** Common config
  */
  hadc1.Instance = ADC1;
  hadc1.Init.ClockPrescaler = ADC_CLOCK_ASYNC_DIV2;
  hadc1.Init.Resolution = ADC_RESOLUTION_12B;
  hadc1.Init.ScanConvMode = ADC_SCAN_DISABLE;
  hadc1.Init.EOCSelection = ADC_EOC_SINGLE_CONV;
  hadc1.Init.LowPowerAutoWait = DISABLE;
  hadc1.Init.ContinuousConvMode = DISABLE;
  hadc1.Init.NbrOfConversion = 1;
  hadc1.Init.DiscontinuousConvMode = DISABLE;
  hadc1.Init.ExternalTrigConv = ADC_SOFTWARE_START;
  hadc1.Init.ExternalTrigConvEdge = ADC_EXTERNALTRIGCONVEDGE_NONE;
  hadc1.Init.ConversionDataManagement = ADC_CONVERSIONDATA_DR;
  hadc1.Init.Overrun = ADC_OVR_DATA_PRESERVED;
  hadc1.Init.LeftBitShift = ADC_LEFTBITSHIFT_NONE;
  hadc1.Init.OversamplingMode = DISABLE;
  hadc1.Init.Oversampling.Ratio = 1;
  if (HAL_ADC_Init(&hadc1) != HAL_OK)
  {
    Error_Handler();
  }

  /** Configure the ADC multi-mode
  */
  multimode.Mode = ADC_MODE_INDEPENDENT;
  if (HAL_ADCEx_MultiModeConfigChannel(&hadc1, &multimode) != HAL_OK)
  {
    Error_Handler();
  }

  /** Configure Regular Channel
  */
  sConfig.Channel = ADC_CHANNEL_15;
  sConfig.Rank = ADC_REGULAR_RANK_1;
  sConfig.SamplingTime = ADC_SAMPLETIME_1CYCLE_5;
  sConfig.SingleDiff = ADC_SINGLE_ENDED;
  sConfig.OffsetNumber = ADC_OFFSET_NONE;
  sConfig.Offset = 0;
  sConfig.OffsetSignedSaturation = DISABLE;
  if (HAL_ADC_ConfigChannel(&hadc1, &sConfig) != HAL_OK)
  {
    Error_Handler();
  }

}

static void MX_ADC2_Init(void)
{

  ADC_ChannelConfTypeDef sConfig = {0};

  /** Common config
  */
  hadc2.Instance = ADC2;
  hadc2.Init.ClockPrescaler = ADC_CLOCK_ASYNC_DIV2;
  hadc2.Init.Resolution = ADC_RESOLUTION_16B;
  hadc2.Init.ScanConvMode = ADC_SCAN_DISABLE;
  hadc2.Init.EOCSelection = ADC_EOC_SINGLE_CONV;
  hadc2.Init.LowPowerAutoWait = DISABLE;
  hadc2.Init.ContinuousConvMode = DISABLE;
  hadc2.Init.NbrOfConversion = 1;
  hadc2.Init.DiscontinuousConvMode = DISABLE;
  hadc2.Init.ExternalTrigConv = ADC_SOFTWARE_START;
  hadc2.Init.ExternalTrigConvEdge = ADC_EXTERNALTRIGCONVEDGE_NONE;
  hadc2.Init.ConversionDataManagement = ADC_CONVERSIONDATA_DR;
  hadc2.Init.Overrun = ADC_OVR_DATA_PRESERVED;
  hadc2.Init.LeftBitShift = ADC_LEFTBITSHIFT_NONE;
  hadc2.Init.OversamplingMode = DISABLE;
  hadc2.Init.Oversampling.Ratio = 1;
  if (HAL_ADC_Init(&hadc2) != HAL_OK)
  {
    Error_Handler();
  }

  /** Configure Regular Channel
  */
  sConfig.Channel = ADC_CHANNEL_8;
  sConfig.Rank = ADC_REGULAR_RANK_1;
  sConfig.SamplingTime = ADC_SAMPLETIME_1CYCLE_5;
  sConfig.SingleDiff = ADC_SINGLE_ENDED;
  sConfig.OffsetNumber = ADC_OFFSET_NONE;
  sConfig.Offset = 0;
  sConfig.OffsetSignedSaturation = DISABLE;
  if (HAL_ADC_ConfigChannel(&hadc2, &sConfig) != HAL_OK)
  {
    Error_Handler();
  }

}

static void MX_ADC3_Init(void)
{

  ADC_ChannelConfTypeDef sConfig = {0};

  /** Common config
  */
  hadc3.Instance = ADC3;
  hadc3.Init.ClockPrescaler = ADC_CLOCK_ASYNC_DIV1;
  hadc3.Init.Resolution = ADC_RESOLUTION_12B;
  hadc3.Init.DataAlign = ADC3_DATAALIGN_RIGHT;
  hadc3.Init.ScanConvMode = ADC_SCAN_DISABLE;
  hadc3.Init.EOCSelection = ADC_EOC_SINGLE_CONV;
  hadc3.Init.LowPowerAutoWait = DISABLE;
  hadc3.Init.ContinuousConvMode = DISABLE;
  hadc3.Init.NbrOfConversion = 1;
  hadc3.Init.DiscontinuousConvMode = DISABLE;
  hadc3.Init.ExternalTrigConv = ADC_SOFTWARE_START;
  hadc3.Init.ExternalTrigConvEdge = ADC_EXTERNALTRIGCONVEDGE_NONE;
  hadc3.Init.DMAContinuousRequests = DISABLE;
  hadc3.Init.SamplingMode = ADC_SAMPLING_MODE_NORMAL;
  hadc3.Init.ConversionDataManagement = ADC_CONVERSIONDATA_DR;
  hadc3.Init.Overrun = ADC_OVR_DATA_PRESERVED;
  hadc3.Init.LeftBitShift = ADC_LEFTBITSHIFT_NONE;
  hadc3.Init.OversamplingMode = DISABLE;
  hadc3.Init.Oversampling.Ratio = ADC3_OVERSAMPLING_RATIO_2;
  if (HAL_ADC_Init(&hadc3) != HAL_OK)
  {
    Error_Handler();
  }

  /** Configure Regular Channel
  */
  sConfig.Channel = ADC_CHANNEL_5;
  sConfig.Rank = ADC_REGULAR_RANK_1;
  sConfig.SamplingTime = ADC3_SAMPLETIME_2CYCLES_5;
  sConfig.SingleDiff = ADC_SINGLE_ENDED;
  sConfig.OffsetNumber = ADC_OFFSET_NONE;
  sConfig.Offset = 0;
  sConfig.OffsetSign = ADC3_OFFSET_SIGN_NEGATIVE;
  if (HAL_ADC_ConfigChannel(&hadc3, &sConfig) != HAL_OK)
  {
    Error_Handler();
  }

}

static void MX_CRC_Init(void)
{

  hcrc.Instance = CRC;
  hcrc.Init.DefaultPolynomialUse = DEFAULT_POLYNOMIAL_ENABLE;
  hcrc.Init.DefaultInitValueUse = DEFAULT_INIT_VALUE_ENABLE;
  hcrc.Init.InputDataInversionMode = CRC_INPUTDATA_INVERSION_NONE;
  hcrc.Init.OutputDataInversionMode = CRC_OUTPUTDATA_INVERSION_DISABLE;
  hcrc.InputDataFormat = CRC_INPUTDATA_FORMAT_BYTES;
  if (HAL_CRC_Init(&hcrc) != HAL_OK)
  {
    Error_Handler();
  }

}

static void MX_DAC1_Init(void)
{

  DAC_ChannelConfTypeDef sConfig = {0};

  /** DAC Initialization
  */
  hdac1.Instance = DAC1;
  if (HAL_DAC_Init(&hdac1) != HAL_OK)
  {
    Error_Handler();
  }

  /** DAC channel OUT2 config
  */
  sConfig.DAC_SampleAndHold = DAC_SAMPLEANDHOLD_DISABLE;
  sConfig.DAC_Trigger = DAC_TRIGGER_NONE;
  sConfig.DAC_OutputBuffer = DAC_OUTPUTBUFFER_ENABLE;
  sConfig.DAC_ConnectOnChipPeripheral = DAC_CHIPCONNECT_DISABLE;
  sConfig.DAC_UserTrimming = DAC_TRIMMING_FACTORY;
  if (HAL_DAC_ConfigChannel(&hdac1, &sConfig, DAC_CHANNEL_2) != HAL_OK)
  {
    Error_Handler();
  }

}

static void MX_I2C2_Init(void)
{

  hi2c2.Instance = I2C2;
  hi2c2.Init.Timing = 0x308087CA;
  hi2c2.Init.OwnAddress1 = 0;
  hi2c2.Init.AddressingMode = I2C_ADDRESSINGMODE_7BIT;
  hi2c2.Init.DualAddressMode = I2C_DUALADDRESS_DISABLE;
  hi2c2.Init.OwnAddress2 = 0;
  hi2c2.Init.OwnAddress2Masks = I2C_OA2_NOMASK;
  hi2c2.Init.GeneralCallMode = I2C_GENERALCALL_DISABLE;
  hi2c2.Init.NoStretchMode = I2C_NOSTRETCH_DISABLE;
  if (HAL_I2C_Init(&hi2c2) != HAL_OK)
  {
    Error_Handler();
  }

  /** Configure Analogue filter
  */
  if (HAL_I2CEx_ConfigAnalogFilter(&hi2c2, I2C_ANALOGFILTER_ENABLE) != HAL_OK)
  {
    Error_Handler();
  }

  /** Configure Digital filter
  */
  if (HAL_I2CEx_ConfigDigitalFilter(&hi2c2, 0) != HAL_OK)
  {
    Error_Handler();
  }

}

static void MX_IWDG1_Init(void)
{

  hiwdg1.Instance = IWDG1;
  hiwdg1.Init.Prescaler = IWDG_PRESCALER_256;
  hiwdg1.Init.Window = 4095;
  hiwdg1.Init.Reload = 4095;
  if (HAL_IWDG_Init(&hiwdg1) != HAL_OK)
  {
    Error_Handler();
  }
  /* USER CODE BEGIN IWDG1_Init 2 */

  /* Congela il conteggio IWDG1 quando il core e' fermato dal debugger (bit
   * nel dominio debug, DBGMCU->APB4FZ1 - non tocca il comportamento in
   * produzione, ha effetto SOLO con un probe collegato e il core in halt).
   * Aggiunto 2026-07-30 su segnalazione utente ("il debug non funziona, il
   * micro si resetta per IWDG") - stessa aggiunta fatta in
   * MMC_Bootloader/Core/Src/main.c. */
  __HAL_DBGMCU_FREEZE_IWDG1();

  /* USER CODE END IWDG1_Init 2 */

}

static void MX_RTC_Init(void)
{

  /** Initialize RTC Only
  */
  hrtc.Instance = RTC;
  hrtc.Init.HourFormat = RTC_HOURFORMAT_24;
  hrtc.Init.AsynchPrediv = 127;
  hrtc.Init.SynchPrediv = 255;
  hrtc.Init.OutPut = RTC_OUTPUT_DISABLE;
  hrtc.Init.OutPutPolarity = RTC_OUTPUT_POLARITY_HIGH;
  hrtc.Init.OutPutType = RTC_OUTPUT_TYPE_OPENDRAIN;
  hrtc.Init.OutPutRemap = RTC_OUTPUT_REMAP_NONE;
  if (HAL_RTC_Init(&hrtc) != HAL_OK)
  {
    Error_Handler();
  }

}

static void MX_SPI3_Init(void)
{

  /* SPI3 parameter configuration*/
  hspi3.Instance = SPI3;
  hspi3.Init.Mode = SPI_MODE_MASTER;
  hspi3.Init.Direction = SPI_DIRECTION_2LINES;
  hspi3.Init.DataSize = SPI_DATASIZE_8BIT;
  hspi3.Init.CLKPolarity = SPI_POLARITY_LOW;
  hspi3.Init.CLKPhase = SPI_PHASE_1EDGE;
  hspi3.Init.NSS = SPI_NSS_SOFT;
  hspi3.Init.BaudRatePrescaler = SPI_BAUDRATEPRESCALER_64;
  hspi3.Init.FirstBit = SPI_FIRSTBIT_MSB;
  hspi3.Init.TIMode = SPI_TIMODE_DISABLE;
  hspi3.Init.CRCCalculation = SPI_CRCCALCULATION_DISABLE;
  hspi3.Init.CRCPolynomial = 0x0;
  hspi3.Init.NSSPMode = SPI_NSS_PULSE_ENABLE;
  hspi3.Init.NSSPolarity = SPI_NSS_POLARITY_LOW;
  hspi3.Init.FifoThreshold = SPI_FIFO_THRESHOLD_01DATA;
  hspi3.Init.TxCRCInitializationPattern = SPI_CRC_INITIALIZATION_ALL_ZERO_PATTERN;
  hspi3.Init.RxCRCInitializationPattern = SPI_CRC_INITIALIZATION_ALL_ZERO_PATTERN;
  hspi3.Init.MasterSSIdleness = SPI_MASTER_SS_IDLENESS_00CYCLE;
  hspi3.Init.MasterInterDataIdleness = SPI_MASTER_INTERDATA_IDLENESS_00CYCLE;
  hspi3.Init.MasterReceiverAutoSusp = SPI_MASTER_RX_AUTOSUSP_DISABLE;
  hspi3.Init.MasterKeepIOState = SPI_MASTER_KEEP_IO_STATE_DISABLE;
  hspi3.Init.IOSwap = SPI_IO_SWAP_DISABLE;
  if (HAL_SPI_Init(&hspi3) != HAL_OK)
  {
    Error_Handler();
  }

}

static void MX_SPI5_Init(void)
{

  /* SPI5 parameter configuration*/
  hspi5.Instance = SPI5;
  hspi5.Init.Mode = SPI_MODE_MASTER;
  hspi5.Init.Direction = SPI_DIRECTION_2LINES;
  hspi5.Init.DataSize = SPI_DATASIZE_8BIT;
  hspi5.Init.CLKPolarity = SPI_POLARITY_LOW;
  hspi5.Init.CLKPhase = SPI_PHASE_2EDGE;
  hspi5.Init.NSS = SPI_NSS_SOFT;
  hspi5.Init.BaudRatePrescaler = SPI_BAUDRATEPRESCALER_16;
  hspi5.Init.FirstBit = SPI_FIRSTBIT_MSB;
  hspi5.Init.TIMode = SPI_TIMODE_DISABLE;
  hspi5.Init.CRCCalculation = SPI_CRCCALCULATION_DISABLE;
  hspi5.Init.CRCPolynomial = 0x0;
  hspi5.Init.NSSPMode = SPI_NSS_PULSE_ENABLE;
  hspi5.Init.NSSPolarity = SPI_NSS_POLARITY_LOW;
  hspi5.Init.FifoThreshold = SPI_FIFO_THRESHOLD_01DATA;
  hspi5.Init.TxCRCInitializationPattern = SPI_CRC_INITIALIZATION_ALL_ZERO_PATTERN;
  hspi5.Init.RxCRCInitializationPattern = SPI_CRC_INITIALIZATION_ALL_ZERO_PATTERN;
  hspi5.Init.MasterSSIdleness = SPI_MASTER_SS_IDLENESS_00CYCLE;
  hspi5.Init.MasterInterDataIdleness = SPI_MASTER_INTERDATA_IDLENESS_00CYCLE;
  hspi5.Init.MasterReceiverAutoSusp = SPI_MASTER_RX_AUTOSUSP_DISABLE;
  hspi5.Init.MasterKeepIOState = SPI_MASTER_KEEP_IO_STATE_DISABLE;
  hspi5.Init.IOSwap = SPI_IO_SWAP_DISABLE;
  if (HAL_SPI_Init(&hspi5) != HAL_OK)
  {
    Error_Handler();
  }

}

static void MX_TIM4_Init(void)
{

  TIM_ClockConfigTypeDef sClockSourceConfig = {0};
  TIM_MasterConfigTypeDef sMasterConfig = {0};
  TIM_IC_InitTypeDef sConfigIC = {0};

  htim4.Instance = TIM4;
  htim4.Init.Prescaler = 0;
  htim4.Init.CounterMode = TIM_COUNTERMODE_UP;
  htim4.Init.Period = 65535;
  htim4.Init.ClockDivision = TIM_CLOCKDIVISION_DIV1;
  htim4.Init.AutoReloadPreload = TIM_AUTORELOAD_PRELOAD_DISABLE;
  if (HAL_TIM_Base_Init(&htim4) != HAL_OK)
  {
    Error_Handler();
  }
  sClockSourceConfig.ClockSource = TIM_CLOCKSOURCE_INTERNAL;
  if (HAL_TIM_ConfigClockSource(&htim4, &sClockSourceConfig) != HAL_OK)
  {
    Error_Handler();
  }
  if (HAL_TIM_IC_Init(&htim4) != HAL_OK)
  {
    Error_Handler();
  }
  sMasterConfig.MasterOutputTrigger = TIM_TRGO_RESET;
  sMasterConfig.MasterSlaveMode = TIM_MASTERSLAVEMODE_DISABLE;
  if (HAL_TIMEx_MasterConfigSynchronization(&htim4, &sMasterConfig) != HAL_OK)
  {
    Error_Handler();
  }
  sConfigIC.ICPolarity = TIM_INPUTCHANNELPOLARITY_RISING;
  sConfigIC.ICSelection = TIM_ICSELECTION_DIRECTTI;
  sConfigIC.ICPrescaler = TIM_ICPSC_DIV1;
  sConfigIC.ICFilter = 0;
  if (HAL_TIM_IC_ConfigChannel(&htim4, &sConfigIC, TIM_CHANNEL_1) != HAL_OK)
  {
    Error_Handler();
  }
  if (HAL_TIM_IC_ConfigChannel(&htim4, &sConfigIC, TIM_CHANNEL_2) != HAL_OK)
  {
    Error_Handler();
  }

}

static void MX_TIM15_Init(void)
{

  TIM_ClockConfigTypeDef sClockSourceConfig = {0};
  TIM_MasterConfigTypeDef sMasterConfig = {0};
  TIM_OC_InitTypeDef sConfigOC = {0};
  TIM_BreakDeadTimeConfigTypeDef sBreakDeadTimeConfig = {0};

  htim15.Instance = TIM15;
  htim15.Init.Prescaler = 549;
  htim15.Init.CounterMode = TIM_COUNTERMODE_UP;
  htim15.Init.Period = 999;
  htim15.Init.ClockDivision = TIM_CLOCKDIVISION_DIV1;
  htim15.Init.RepetitionCounter = 0;
  htim15.Init.AutoReloadPreload = TIM_AUTORELOAD_PRELOAD_DISABLE;
  if (HAL_TIM_Base_Init(&htim15) != HAL_OK)
  {
    Error_Handler();
  }
  sClockSourceConfig.ClockSource = TIM_CLOCKSOURCE_INTERNAL;
  if (HAL_TIM_ConfigClockSource(&htim15, &sClockSourceConfig) != HAL_OK)
  {
    Error_Handler();
  }
  if (HAL_TIM_PWM_Init(&htim15) != HAL_OK)
  {
    Error_Handler();
  }
  sMasterConfig.MasterOutputTrigger = TIM_TRGO_RESET;
  sMasterConfig.MasterSlaveMode = TIM_MASTERSLAVEMODE_DISABLE;
  if (HAL_TIMEx_MasterConfigSynchronization(&htim15, &sMasterConfig) != HAL_OK)
  {
    Error_Handler();
  }
  sConfigOC.OCMode = TIM_OCMODE_PWM1;
  sConfigOC.Pulse = 0;
  sConfigOC.OCPolarity = TIM_OCPOLARITY_HIGH;
  sConfigOC.OCNPolarity = TIM_OCNPOLARITY_HIGH;
  sConfigOC.OCFastMode = TIM_OCFAST_DISABLE;
  sConfigOC.OCIdleState = TIM_OCIDLESTATE_RESET;
  sConfigOC.OCNIdleState = TIM_OCNIDLESTATE_RESET;
  if (HAL_TIM_PWM_ConfigChannel(&htim15, &sConfigOC, TIM_CHANNEL_1) != HAL_OK)
  {
    Error_Handler();
  }
  if (HAL_TIM_PWM_ConfigChannel(&htim15, &sConfigOC, TIM_CHANNEL_2) != HAL_OK)
  {
    Error_Handler();
  }
  sBreakDeadTimeConfig.OffStateRunMode = TIM_OSSR_DISABLE;
  sBreakDeadTimeConfig.OffStateIDLEMode = TIM_OSSI_DISABLE;
  sBreakDeadTimeConfig.LockLevel = TIM_LOCKLEVEL_OFF;
  sBreakDeadTimeConfig.DeadTime = 0;
  sBreakDeadTimeConfig.BreakState = TIM_BREAK_DISABLE;
  sBreakDeadTimeConfig.BreakPolarity = TIM_BREAKPOLARITY_HIGH;
  sBreakDeadTimeConfig.BreakFilter = 0;
  sBreakDeadTimeConfig.AutomaticOutput = TIM_AUTOMATICOUTPUT_DISABLE;
  if (HAL_TIMEx_ConfigBreakDeadTime(&htim15, &sBreakDeadTimeConfig) != HAL_OK)
  {
    Error_Handler();
  }
  HAL_TIM_MspPostInit(&htim15);

}

static void MX_TIM16_Init(void)
{

  htim16.Instance = TIM16;
  htim16.Init.Prescaler = 0;
  htim16.Init.CounterMode = TIM_COUNTERMODE_UP;
  htim16.Init.Period = 65535;
  htim16.Init.ClockDivision = TIM_CLOCKDIVISION_DIV1;
  htim16.Init.RepetitionCounter = 0;
  htim16.Init.AutoReloadPreload = TIM_AUTORELOAD_PRELOAD_DISABLE;
  if (HAL_TIM_Base_Init(&htim16) != HAL_OK)
  {
    Error_Handler();
  }

}

static void MX_USART1_UART_Init(void)
{

  huart1.Instance = USART1;
  huart1.Init.BaudRate = 115200;
  huart1.Init.WordLength = UART_WORDLENGTH_8B;
  huart1.Init.StopBits = UART_STOPBITS_1;
  huart1.Init.Parity = UART_PARITY_NONE;
  huart1.Init.Mode = UART_MODE_TX_RX;
  huart1.Init.HwFlowCtl = UART_HWCONTROL_NONE;
  huart1.Init.OverSampling = UART_OVERSAMPLING_16;
  huart1.Init.OneBitSampling = UART_ONE_BIT_SAMPLE_DISABLE;
  huart1.Init.ClockPrescaler = UART_PRESCALER_DIV1;
  huart1.AdvancedInit.AdvFeatureInit = UART_ADVFEATURE_NO_INIT;
  if (HAL_RS485Ex_Init(&huart1, UART_DE_POLARITY_HIGH, 0, 0) != HAL_OK)
  {
    Error_Handler();
  }
  if (HAL_UARTEx_SetTxFifoThreshold(&huart1, UART_TXFIFO_THRESHOLD_1_8) != HAL_OK)
  {
    Error_Handler();
  }
  if (HAL_UARTEx_SetRxFifoThreshold(&huart1, UART_RXFIFO_THRESHOLD_1_8) != HAL_OK)
  {
    Error_Handler();
  }
  if (HAL_UARTEx_DisableFifoMode(&huart1) != HAL_OK)
  {
    Error_Handler();
  }
  /* USER CODE BEGIN USART1_Init 2 */
  /* Disabilita overrun error: se il master invia dati durante il boot
   * (prima di HAL_UART_Receive_IT) non si accumula ORE che poi
   * abborterebbe la prima ricezione IT.  Il byte più vecchio rimane in
   * RDR e viene riletto correttamente; eventuali byte successivi vanno
   * persi silenziosamente (accettabile per ASCII command-response). */
  SET_BIT(huart1.Instance->CR3, USART_CR3_OVRDIS);
  /* USER CODE END USART1_Init 2 */

}

static void MX_USART6_UART_Init(void)
{

  huart6.Instance = USART6;
  huart6.Init.BaudRate = 115200;
  huart6.Init.WordLength = UART_WORDLENGTH_8B;
  huart6.Init.StopBits = UART_STOPBITS_1;
  huart6.Init.Parity = UART_PARITY_NONE;
  huart6.Init.Mode = UART_MODE_TX_RX;
  huart6.Init.HwFlowCtl = UART_HWCONTROL_NONE;
  huart6.Init.OverSampling = UART_OVERSAMPLING_16;
  huart6.Init.OneBitSampling = UART_ONE_BIT_SAMPLE_DISABLE;
  huart6.Init.ClockPrescaler = UART_PRESCALER_DIV1;
  huart6.AdvancedInit.AdvFeatureInit = UART_ADVFEATURE_NO_INIT;
  if (HAL_UART_Init(&huart6) != HAL_OK)
  {
    Error_Handler();
  }
  if (HAL_UARTEx_SetTxFifoThreshold(&huart6, UART_TXFIFO_THRESHOLD_1_8) != HAL_OK)
  {
    Error_Handler();
  }
  if (HAL_UARTEx_SetRxFifoThreshold(&huart6, UART_RXFIFO_THRESHOLD_1_8) != HAL_OK)
  {
    Error_Handler();
  }
  if (HAL_UARTEx_DisableFifoMode(&huart6) != HAL_OK)
  {
    Error_Handler();
  }

}

static void MX_USART10_UART_Init(void)
{

  huart10.Instance = USART10;
  huart10.Init.BaudRate = 115200;
  huart10.Init.WordLength = UART_WORDLENGTH_8B;
  huart10.Init.StopBits = UART_STOPBITS_1;
  huart10.Init.Parity = UART_PARITY_NONE;
  huart10.Init.Mode = UART_MODE_TX_RX;
  huart10.Init.HwFlowCtl = UART_HWCONTROL_NONE;
  huart10.Init.OverSampling = UART_OVERSAMPLING_16;
  huart10.Init.OneBitSampling = UART_ONE_BIT_SAMPLE_DISABLE;
  huart10.Init.ClockPrescaler = UART_PRESCALER_DIV1;
  huart10.AdvancedInit.AdvFeatureInit = UART_ADVFEATURE_NO_INIT;
  if (HAL_UART_Init(&huart10) != HAL_OK)
  {
    Error_Handler();
  }
  if (HAL_UARTEx_SetTxFifoThreshold(&huart10, UART_TXFIFO_THRESHOLD_1_8) != HAL_OK)
  {
    Error_Handler();
  }
  if (HAL_UARTEx_SetRxFifoThreshold(&huart10, UART_RXFIFO_THRESHOLD_1_8) != HAL_OK)
  {
    Error_Handler();
  }
  if (HAL_UARTEx_DisableFifoMode(&huart10) != HAL_OK)
  {
    Error_Handler();
  }

}

static void MX_DMA_Init(void)
{

  /* DMA controller clock enable */
  __HAL_RCC_DMA1_CLK_ENABLE();

  /* DMA interrupt init */
  /* DMA1_Stream0_IRQn interrupt configuration */
  HAL_NVIC_SetPriority(DMA1_Stream0_IRQn, 5, 0);
  HAL_NVIC_EnableIRQ(DMA1_Stream0_IRQn);
  /* DMA1_Stream1_IRQn interrupt configuration */
  HAL_NVIC_SetPriority(DMA1_Stream1_IRQn, 5, 0);
  HAL_NVIC_EnableIRQ(DMA1_Stream1_IRQn);
  /* DMA1_Stream2_IRQn interrupt configuration */
  HAL_NVIC_SetPriority(DMA1_Stream2_IRQn, 5, 0);
  HAL_NVIC_EnableIRQ(DMA1_Stream2_IRQn);
  /* DMA1_Stream3_IRQn interrupt configuration */
  HAL_NVIC_SetPriority(DMA1_Stream3_IRQn, 5, 0);
  HAL_NVIC_EnableIRQ(DMA1_Stream3_IRQn);
  /* DMA1_Stream4_IRQn interrupt configuration */
  HAL_NVIC_SetPriority(DMA1_Stream4_IRQn, 5, 0);
  HAL_NVIC_EnableIRQ(DMA1_Stream4_IRQn);
  /* DMA1_Stream5_IRQn interrupt configuration */
  HAL_NVIC_SetPriority(DMA1_Stream5_IRQn, 5, 0);
  HAL_NVIC_EnableIRQ(DMA1_Stream5_IRQn);

}

static void MX_GPIO_Init(void)
{
  GPIO_InitTypeDef GPIO_InitStruct = {0};

  /* GPIO Ports Clock Enable */
  __HAL_RCC_GPIOE_CLK_ENABLE();
  __HAL_RCC_GPIOC_CLK_ENABLE();
  __HAL_RCC_GPIOF_CLK_ENABLE();
  __HAL_RCC_GPIOH_CLK_ENABLE();
  __HAL_RCC_GPIOA_CLK_ENABLE();
  __HAL_RCC_GPIOB_CLK_ENABLE();
  __HAL_RCC_GPIOG_CLK_ENABLE();
  __HAL_RCC_GPIOD_CLK_ENABLE();

  /*Configure GPIO pin Output Level */
  HAL_GPIO_WritePin(GPIOE, AUX_LED_Pin|AIMING_ENABLE_Pin|nLASE_Q_PWR_SHDN_Pin, GPIO_PIN_RESET);

  /*Configure GPIO pin Output Level */
  HAL_GPIO_WritePin(GPIOF, nTH_SENS_RESET_Pin|LASE_Q_485_DIR_Pin|HW_SETPOINT_SEL_Pin, GPIO_PIN_RESET);

  /*Configure GPIO pin Output Level */
  HAL_GPIO_WritePin(GPIOF, TEMP_ADC_nCS_Pin|nLASE_Q_INTLCK_Pin, GPIO_PIN_SET);

  /*Configure GPIO pin Output Level */
  HAL_GPIO_WritePin(nSAB_PWR_SHDN_GPIO_Port, nSAB_PWR_SHDN_Pin, GPIO_PIN_RESET);

  /*Configure GPIO pin Output Level */
  HAL_GPIO_WritePin(nSAB_EN_GPIO_Port, nSAB_EN_Pin, GPIO_PIN_SET);

  /*Configure GPIO pin Output Level */
  HAL_GPIO_WritePin(GPIOE, nMCU2_RST_Pin|nLASE_Q_EN_Pin|nHW_SETPOINT_EN_Pin|nGATE_MC_Pin
                          |nGATE_HW_EN_Pin|nLED_BLUE_Pin|nWATER_VALVE_EN_Pin, GPIO_PIN_SET);

  /*Configure GPIO pin Output Level */
  HAL_GPIO_WritePin(GPIOB, nPSU1_ON_Pin|nPSU2_ON_Pin|nLED_RED_Pin|nLED_GREEN_Pin, GPIO_PIN_SET);

  /*Configure GPIO pin Output Level */
  HAL_GPIO_WritePin(GPIOD, CONTACTOR_1_ON_Pin|MAIN_PWR_SHDN_Pin|nCOM_PWR_SHDN_Pin, GPIO_PIN_RESET);

  /*Configure GPIO pin Output Level */
  HAL_GPIO_WritePin(GPIOG, nREDUCED_SETPOINT_RANGE_Pin|nCMD_RDY_iso_Pin|nREADY_iso_Pin|nSD_CS_Pin, GPIO_PIN_SET);

  /*Configure GPIO pin Output Level */
  HAL_GPIO_WritePin(GPIOC, nEMISSION_RDY_iso_Pin|nAIMING_ON_iso_Pin|nERROR_iso_Pin|nWATER_VALVE_STATUS_Pin, GPIO_PIN_SET);

  /*Configure GPIO pin Output Level */
  HAL_GPIO_WritePin(GPIOA, nEXT_485_TERMINATION_Pin|CONTACTOR_2_ON_Pin, GPIO_PIN_RESET);

  /*Configure GPIO pin Output Level */
  HAL_GPIO_WritePin(GPIOD, COM_SPI_nCS_Pin|nCOM_INT_OUT_Pin, GPIO_PIN_SET);

  /*Configure GPIO pins : LID1_OPEN_Pin LID2_OPEN_Pin nLASE_Q_PWR_FLT_Pin */
  GPIO_InitStruct.Pin = LID1_OPEN_Pin|LID2_OPEN_Pin|nLASE_Q_PWR_FLT_Pin;
  GPIO_InitStruct.Mode = GPIO_MODE_INPUT;
  GPIO_InitStruct.Pull = GPIO_NOPULL;
  HAL_GPIO_Init(GPIOE, &GPIO_InitStruct);

  /*Configure GPIO pins : AUX_LED_Pin AIMING_ENABLE_Pin nLASE_Q_EN_Pin nHW_SETPOINT_EN_Pin
                           nGATE_MC_Pin nGATE_HW_EN_Pin nLASE_Q_PWR_SHDN_Pin nLED_BLUE_Pin
                           nWATER_VALVE_EN_Pin */
  GPIO_InitStruct.Pin = AUX_LED_Pin|AIMING_ENABLE_Pin|nLASE_Q_EN_Pin|nHW_SETPOINT_EN_Pin
                          |nGATE_MC_Pin|nGATE_HW_EN_Pin|nLASE_Q_PWR_SHDN_Pin|nLED_BLUE_Pin
                          |nWATER_VALVE_EN_Pin;
  GPIO_InitStruct.Mode = GPIO_MODE_OUTPUT_PP;
  GPIO_InitStruct.Pull = GPIO_NOPULL;
  GPIO_InitStruct.Speed = GPIO_SPEED_FREQ_LOW;
  HAL_GPIO_Init(GPIOE, &GPIO_InitStruct);

  /*Configure GPIO pins : nKEY_STATUS_A_Pin nKEY_STATUS_B_Pin nSAB_PWR_FLT_Pin nSAB_B_TEST_Pin */
  GPIO_InitStruct.Pin = nKEY_STATUS_A_Pin|nKEY_STATUS_B_Pin|nSAB_PWR_FLT_Pin|nSAB_B_TEST_Pin;
  GPIO_InitStruct.Mode = GPIO_MODE_INPUT;
  GPIO_InitStruct.Pull = GPIO_NOPULL;
  HAL_GPIO_Init(GPIOC, &GPIO_InitStruct);

  /*Configure GPIO pins : nFP_BUTTON_Pin nSAB_INTLCK_B_STATUS_Pin */
  GPIO_InitStruct.Pin = nFP_BUTTON_Pin|nSAB_INTLCK_B_STATUS_Pin;
  GPIO_InitStruct.Mode = GPIO_MODE_IT_RISING_FALLING;
  GPIO_InitStruct.Pull = GPIO_NOPULL;
  HAL_GPIO_Init(GPIOC, &GPIO_InitStruct);

  /*Configure GPIO pins : nTH_SENS_RESET_Pin TEMP_ADC_nCS_Pin LASE_Q_485_DIR_Pin HW_SETPOINT_SEL_Pin
                           nLASE_Q_INTLCK_Pin */
  GPIO_InitStruct.Pin = nTH_SENS_RESET_Pin|TEMP_ADC_nCS_Pin|LASE_Q_485_DIR_Pin|HW_SETPOINT_SEL_Pin
                          |nLASE_Q_INTLCK_Pin;
  GPIO_InitStruct.Mode = GPIO_MODE_OUTPUT_PP;
  GPIO_InitStruct.Pull = GPIO_NOPULL;
  GPIO_InitStruct.Speed = GPIO_SPEED_FREQ_LOW;
  HAL_GPIO_Init(GPIOF, &GPIO_InitStruct);

  /*Configure GPIO pins : nFLOOD_1_Pin nFLOOD_2_Pin SAB_PWR_GOOD_Pin */
  GPIO_InitStruct.Pin = nFLOOD_1_Pin|nFLOOD_2_Pin|SAB_PWR_GOOD_Pin;
  GPIO_InitStruct.Mode = GPIO_MODE_INPUT;
  GPIO_InitStruct.Pull = GPIO_NOPULL;
  HAL_GPIO_Init(GPIOF, &GPIO_InitStruct);

  /*Configure GPIO pins : nSAB_PWR_SHDN_Pin nEMISSION_RDY_iso_Pin nAIMING_ON_iso_Pin nERROR_iso_Pin
                           nWATER_VALVE_STATUS_Pin */
  GPIO_InitStruct.Pin = nSAB_PWR_SHDN_Pin|nEMISSION_RDY_iso_Pin|nAIMING_ON_iso_Pin|nERROR_iso_Pin
                          |nWATER_VALVE_STATUS_Pin;
  GPIO_InitStruct.Mode = GPIO_MODE_OUTPUT_PP;
  GPIO_InitStruct.Pull = GPIO_NOPULL;
  GPIO_InitStruct.Speed = GPIO_SPEED_FREQ_LOW;
  HAL_GPIO_Init(GPIOC, &GPIO_InitStruct);

  /*Configure GPIO pin : nSAB_INTLCK_A_STATUS_Pin */
  GPIO_InitStruct.Pin = nSAB_INTLCK_A_STATUS_Pin;
  GPIO_InitStruct.Mode = GPIO_MODE_IT_RISING_FALLING;
  GPIO_InitStruct.Pull = GPIO_NOPULL;
  HAL_GPIO_Init(nSAB_INTLCK_A_STATUS_GPIO_Port, &GPIO_InitStruct);

  /*Configure GPIO pins : nSAB_EN_Pin nEXT_485_TERMINATION_Pin CONTACTOR_2_ON_Pin */
  GPIO_InitStruct.Pin = nSAB_EN_Pin|nEXT_485_TERMINATION_Pin|CONTACTOR_2_ON_Pin;
  GPIO_InitStruct.Mode = GPIO_MODE_OUTPUT_PP;
  GPIO_InitStruct.Pull = GPIO_NOPULL;
  GPIO_InitStruct.Speed = GPIO_SPEED_FREQ_LOW;
  HAL_GPIO_Init(GPIOA, &GPIO_InitStruct);

  /*Configure GPIO pin : nSAB_A_TEST_Pin */
  GPIO_InitStruct.Pin = nSAB_A_TEST_Pin;
  GPIO_InitStruct.Mode = GPIO_MODE_INPUT;
  GPIO_InitStruct.Pull = GPIO_NOPULL;
  HAL_GPIO_Init(nSAB_A_TEST_GPIO_Port, &GPIO_InitStruct);

  /*Configure GPIO pins : LASE_Q_OUT_Pin nENABLE_IN_iso_Pin nAIMING_iso_Pin nCLR_ERR_iso_Pin */
  GPIO_InitStruct.Pin = LASE_Q_OUT_Pin|nENABLE_IN_iso_Pin|nAIMING_iso_Pin|nCLR_ERR_iso_Pin;
  GPIO_InitStruct.Mode = GPIO_MODE_INPUT;
  GPIO_InitStruct.Pull = GPIO_NOPULL;
  HAL_GPIO_Init(GPIOG, &GPIO_InitStruct);

  /*Configure GPIO pin : nMCU2_RST_Pin */
  GPIO_InitStruct.Pin = nMCU2_RST_Pin;
  GPIO_InitStruct.Mode = GPIO_MODE_OUTPUT_OD;
  GPIO_InitStruct.Pull = GPIO_NOPULL;
  GPIO_InitStruct.Speed = GPIO_SPEED_FREQ_LOW;
  HAL_GPIO_Init(nMCU2_RST_GPIO_Port, &GPIO_InitStruct);

  /*Configure GPIO pin : nHW_SETPOINT_FLT_Pin */
  GPIO_InitStruct.Pin = nHW_SETPOINT_FLT_Pin;
  GPIO_InitStruct.Mode = GPIO_MODE_IT_RISING;
  GPIO_InitStruct.Pull = GPIO_NOPULL;
  HAL_GPIO_Init(nHW_SETPOINT_FLT_GPIO_Port, &GPIO_InitStruct);

  /*Configure GPIO pins : LASE_Q_PWR_GOOD_Pin nPSU1_DC_OK_Pin nPSU2_DC_OK_Pin nSD_PRESENT_Pin */
  GPIO_InitStruct.Pin = LASE_Q_PWR_GOOD_Pin|nPSU1_DC_OK_Pin|nPSU2_DC_OK_Pin|nSD_PRESENT_Pin;
  GPIO_InitStruct.Mode = GPIO_MODE_INPUT;
  GPIO_InitStruct.Pull = GPIO_NOPULL;
  HAL_GPIO_Init(GPIOB, &GPIO_InitStruct);

  /*Configure GPIO pins : nPSU1_ON_Pin nPSU2_ON_Pin nLED_RED_Pin nLED_GREEN_Pin */
  GPIO_InitStruct.Pin = nPSU1_ON_Pin|nPSU2_ON_Pin|nLED_RED_Pin|nLED_GREEN_Pin;
  GPIO_InitStruct.Mode = GPIO_MODE_OUTPUT_PP;
  GPIO_InitStruct.Pull = GPIO_NOPULL;
  GPIO_InitStruct.Speed = GPIO_SPEED_FREQ_LOW;
  HAL_GPIO_Init(GPIOB, &GPIO_InitStruct);

  /*Configure GPIO pin : PSU1_ALARM_Pin */
  GPIO_InitStruct.Pin = PSU1_ALARM_Pin;
  GPIO_InitStruct.Mode = GPIO_MODE_IT_RISING_FALLING;
  GPIO_InitStruct.Pull = GPIO_NOPULL;
  HAL_GPIO_Init(PSU1_ALARM_GPIO_Port, &GPIO_InitStruct);

  /*Configure GPIO pin : PSU2_ALARM_Pin */
  GPIO_InitStruct.Pin = PSU2_ALARM_Pin;
  GPIO_InitStruct.Mode = GPIO_MODE_IT_RISING_FALLING;
  GPIO_InitStruct.Pull = GPIO_NOPULL;
  HAL_GPIO_Init(PSU2_ALARM_GPIO_Port, &GPIO_InitStruct);

  /*Configure GPIO pins : CONTACTOR_1_ON_Pin MAIN_PWR_SHDN_Pin COM_SPI_nCS_Pin nCOM_INT_OUT_Pin
                           nCOM_PWR_SHDN_Pin */
  GPIO_InitStruct.Pin = CONTACTOR_1_ON_Pin|MAIN_PWR_SHDN_Pin|COM_SPI_nCS_Pin|nCOM_INT_OUT_Pin
                          |nCOM_PWR_SHDN_Pin;
  GPIO_InitStruct.Mode = GPIO_MODE_OUTPUT_PP;
  GPIO_InitStruct.Pull = GPIO_NOPULL;
  GPIO_InitStruct.Speed = GPIO_SPEED_FREQ_LOW;
  HAL_GPIO_Init(GPIOD, &GPIO_InitStruct);

  /*Configure GPIO pins : MAIN_PWR_GOOD_Pin nVEXT_GOOD_Pin nEXT_CTL_iso_Pin nSYS_ON_iso_Pin
                           COM_PWR_GOOD_Pin CONTACTOR_2_STATUS_Pin CONTACTOR_1_STATUS_Pin */
  GPIO_InitStruct.Pin = MAIN_PWR_GOOD_Pin|nVEXT_GOOD_Pin|nEXT_CTL_iso_Pin|nSYS_ON_iso_Pin
                          |COM_PWR_GOOD_Pin|CONTACTOR_2_STATUS_Pin|CONTACTOR_1_STATUS_Pin;
  GPIO_InitStruct.Mode = GPIO_MODE_INPUT;
  GPIO_InitStruct.Pull = GPIO_NOPULL;
  HAL_GPIO_Init(GPIOD, &GPIO_InitStruct);

  /*Configure GPIO pins : nMAIN_PWR_FLT_5V_Pin nCOM_PWR_FLT_Pin */
  GPIO_InitStruct.Pin = nMAIN_PWR_FLT_5V_Pin|nCOM_PWR_FLT_Pin;
  GPIO_InitStruct.Mode = GPIO_MODE_IT_RISING;
  GPIO_InitStruct.Pull = GPIO_NOPULL;
  HAL_GPIO_Init(GPIOD, &GPIO_InitStruct);

  /*Configure GPIO pin : nGATE_IN_iso_Pin */
  GPIO_InitStruct.Pin = nGATE_IN_iso_Pin;
  GPIO_InitStruct.Mode = GPIO_MODE_IT_RISING;
  GPIO_InitStruct.Pull = GPIO_NOPULL;
  HAL_GPIO_Init(nGATE_IN_iso_GPIO_Port, &GPIO_InitStruct);

  /*Configure GPIO pins : nREDUCED_SETPOINT_RANGE_Pin nCMD_RDY_iso_Pin nREADY_iso_Pin nSD_CS_Pin */
  GPIO_InitStruct.Pin = nREDUCED_SETPOINT_RANGE_Pin|nCMD_RDY_iso_Pin|nREADY_iso_Pin|nSD_CS_Pin;
  GPIO_InitStruct.Mode = GPIO_MODE_OUTPUT_PP;
  GPIO_InitStruct.Pull = GPIO_NOPULL;
  GPIO_InitStruct.Speed = GPIO_SPEED_FREQ_LOW;
  HAL_GPIO_Init(GPIOG, &GPIO_InitStruct);

  /*Configure GPIO pin : nCOM_INT_IN_Pin */
  GPIO_InitStruct.Pin = nCOM_INT_IN_Pin;
  GPIO_InitStruct.Mode = GPIO_MODE_IT_FALLING;
  GPIO_InitStruct.Pull = GPIO_NOPULL;
  HAL_GPIO_Init(nCOM_INT_IN_GPIO_Port, &GPIO_InitStruct);

  /*AnalogSwitch Config */
  HAL_SYSCFG_AnalogSwitchConfig(SYSCFG_SWITCH_PA1, SYSCFG_SWITCH_PA1_CLOSE);

  /* EXTI interrupt init*/
  HAL_NVIC_SetPriority(nSAB_INTLCK_A_STATUS_EXTI_IRQn, 5, 0);
  HAL_NVIC_EnableIRQ(nSAB_INTLCK_A_STATUS_EXTI_IRQn);

  HAL_NVIC_SetPriority(nCOM_INT_IN_EXTI_IRQn, 5, 0);
  HAL_NVIC_EnableIRQ(nCOM_INT_IN_EXTI_IRQn);

  HAL_NVIC_SetPriority(nSAB_INTLCK_B_STATUS_EXTI_IRQn, 5, 0);
  HAL_NVIC_EnableIRQ(nSAB_INTLCK_B_STATUS_EXTI_IRQn);

  HAL_NVIC_SetPriority(nCOM_PWR_FLT_EXTI_IRQn, 5, 0);
  HAL_NVIC_EnableIRQ(nCOM_PWR_FLT_EXTI_IRQn);

  HAL_NVIC_SetPriority(nGATE_IN_iso_EXTI_IRQn, 5, 0);
  HAL_NVIC_EnableIRQ(nGATE_IN_iso_EXTI_IRQn);

  HAL_NVIC_SetPriority(nHW_SETPOINT_FLT_EXTI_IRQn, 5, 0);
  HAL_NVIC_EnableIRQ(nHW_SETPOINT_FLT_EXTI_IRQn);

}

void StartDefaultTask(void *argument)
{
  /* USER CODE BEGIN 5 */
  /* Infinite loop.
   * Watchdog_Service() gira qui perché questo task esegue sempre, ad ogni
   * tick, indipendentemente dallo stato degli altri task applicativi: è
   * il contesto giusto da cui decidere se rinfrescare IWDG1, ma la decisione
   * vera (tutti i task vivi?) è dentro Watchdog_Service() stesso, non qui. */
  for(;;)
  {
    Watchdog_Service();
    osDelay(1);
  }
  /* USER CODE END 5 */
}

 /* MPU Configuration */

void MPU_Config(void)
{
  MPU_Region_InitTypeDef MPU_InitStruct = {0};

  /* Disables the MPU */
  HAL_MPU_Disable();

  /** Initializes and configures the Region and the memory to be protected
  */
  MPU_InitStruct.Enable = MPU_REGION_ENABLE;
  MPU_InitStruct.Number = MPU_REGION_NUMBER0;
  MPU_InitStruct.BaseAddress = 0x0;
  MPU_InitStruct.Size = MPU_REGION_SIZE_4GB;
  MPU_InitStruct.SubRegionDisable = 0x87;
  MPU_InitStruct.TypeExtField = MPU_TEX_LEVEL0;
  MPU_InitStruct.AccessPermission = MPU_REGION_NO_ACCESS;
  MPU_InitStruct.DisableExec = MPU_INSTRUCTION_ACCESS_DISABLE;
  MPU_InitStruct.IsShareable = MPU_ACCESS_SHAREABLE;
  MPU_InitStruct.IsCacheable = MPU_ACCESS_NOT_CACHEABLE;
  MPU_InitStruct.IsBufferable = MPU_ACCESS_NOT_BUFFERABLE;

  HAL_MPU_ConfigRegion(&MPU_InitStruct);
  /* Enables the MPU */
  HAL_MPU_Enable(MPU_PRIVILEGED_DEFAULT);

}

void HAL_TIM_PeriodElapsedCallback(TIM_HandleTypeDef *htim)
{
  if (htim->Instance == TIM1)
  {
    HAL_IncTick();
  }
  /* USER CODE BEGIN Callback 1 */
  else if (htim->Instance == TIM16)
  {
    /* QCW: impulsazione nGATE_MC (vedi Drivers/QCW/QCW.h). TIM16 gestito
     * da CubeMX (MX_TIM16_Init() sopra); prescaler/ARR "veri" sono
     * ricalcolati dinamicamente da QCW_SetParams() ad ogni cambio
     * frequenza/duty (range 1Hz-50kHz) e applicati qui via
     * QCW_TimerCallback(). */
    QCW_TimerCallback();
  }
  else if (htim->Instance == TIM4)
  {
    /* Flow meter (vedi Drivers/FlowMeter/FlowMeter.h): conta gli overflow
     * del contatore a 16 bit tra due impulsi consecutivi, necessario per il
     * calcolo corretto del periodo in FlowMeter_CaptureCallback(). */
    FlowMeter_PeriodElapsedCallback(htim);
  }
  /* USER CODE END Callback 1 */
}

void Error_Handler(void)
{
  __disable_irq();
  while (1)
  {
  }
}

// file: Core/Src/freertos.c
/* USER CODE BEGIN Header */
/**
  ******************************************************************************
  * File Name          : freertos.c
  * Description        : Code for freertos applications
  ******************************************************************************
  * @attention
  *
  * Copyright (c) 2026 STMicroelectronics.
  * All rights reserved.
  *
  * This software is licensed under terms that can be found in the LICENSE file
  * in the root directory of this software component.
  * If no LICENSE file comes with this software, it is provided AS-IS.
  *
  ******************************************************************************
  */
/* USER CODE END Header */

#include "FreeRTOS.h"
#include "task.h"
#include "main.h"

/* USER CODE BEGIN Includes */
#include "queues.h"
#include "fsm_events.h"
#include "config.h"
#include "task_comms.h"
#include "task_amc.h"
#include "task_monitor.h"
#include "task_fsm.h"
#include "task_outputs.h"
#include "task_inputs.h"
#include "task_rs485.h"
#include "hal_handles.h"
#include "eFuse.h"
#include "SAB.h"
#include "BoardCtrl.h"
#include "AMC.h"
#include "sys_log.h"
#include "Watchdog.h"
#include "string.h"
#include "SPI3Bus.h"
#include "COM_interface.h"
#include "task_com_interface.h"
#include "QCW.h"
/* USER CODE END Includes */

/* USER CODE BEGIN Variables */

/*
 * Popolato da vApplicationStackOverflowHook() (sotto): nome del task e
 * relativo handle al momento dell'overflow rilevato. Ispezionabile nel
 * debugger (Expressions: g_ovfTaskName / g_ovfTaskHandle) quando si ferma
 * su BKPT. Vedi anche configCHECK_FOR_STACK_OVERFLOW in FreeRTOSConfig.h.
 */
volatile char        g_ovfTaskName[configMAX_TASK_NAME_LEN];
volatile TaskHandle_t g_ovfTaskHandle;

/* USER CODE END Variables */

/* USER CODE BEGIN Application */

/* Callback SAB: traduce eventi driver in eventi FSM.
 *
 * SAB_EVT_ARMED non genera un evento FSM: action_enter_enabled() rileva
 * l'armo direttamente interrogando SAB_GetState() nel suo loop di polling.
 * Gli altri eventi (fault) sono postati alla coda e processati dalla FSM
 * quando action_enter_enabled() ritorna (stato già SYS_ENABLED a quel punto,
 * la FSM transita poi in SYS_ERROR).
 *
 * MASCHERABILITÀ (g_config.error_mask): il log su SD resta SEMPRE scritto
 * (traccia diagnostica indipendente dalla maschera); solo il post
 * dell'evento FSM è condizionato al bit ERR_BIT_SAB_x — a differenza di
 * FLOOD/FLOW/TEMP/PSU (gestiti in task_monitor.c), questi bit prima non
 * erano mai controllati da nessuna parte: la maschera non aveva alcun
 * effetto sui fault SAB.
 *
 * DISCRIMINAZIONE CANALE A/B (dal 2026-07-15): SAB_EVT_INTERLOCK_OPEN e
 * SAB_EVT_TEST_FAIL restano eventi generici (SAB.h/SAB.c non distinguono
 * il canale nella callback), ma qui il canale specifico si ricostruisce
 * con SAB_GetInterlockStatus()/SAB_GetTestStatus() e viene mascherato
 * INDIPENDENTEMENTE per canale (ERR_BIT_SAB_INTLCK_A/B,
 * ERR_BIT_SAB_TEST_A/B — vedi task_monitor.h).
 *
 * ATTENZIONE — INTLCK vs TEST (rivisto 2026-07-16): i due canali INTLCK
 * sono la STESSA catena di sicurezza duplicata per ridondanza (non varianti
 * di prodotto come KEY_A/B o LID1/2): mascherare un canale INTLCK REALMENTE
 * cablato sopprime solo la notifica verso la FSM di sistema, MAI la
 * risposta di sicurezza del modulo SAB (che va comunque in SAB_STATE_FAULT
 * su qualsiasi canale interlock, indipendentemente da error_mask) — usare
 * la maschera INTLCK solo per banco prova/debug a canale singolo. I canali
 * TEST invece, da questo bugfix, sono già filtrati a monte da
 * test_pins_ok() (SAB.c): un canale TEST mascherato non genera nemmeno più
 * SAB_EVT_TEST_FAIL per quel canale, quindi il controllo error_mask qui
 * sotto per TEST_A/B è ormai ridondante (ma innocuo) rispetto a quello
 * interno al driver — lasciato per simmetria col ramo INTLCK e perché
 * SAB_GetTestStatus() resta comunque una lettura RAW non mascherata.
 */
static void sab_event_cb(SAB_Evt_t evt)
{
    switch (evt) {
        case SAB_EVT_ARMED:
            /* Rilevato dal polling in action_enter_enabled(): nessuna azione */
            break;
        case SAB_EVT_TIMEOUT: {
            /*
             * BUGFIX (Luca, 2026-07-16): a differenza di SAB_EVT_INTERLOCK_OPEN
             * sotto, questo log non riportava MAI quale canale (A/B) non si
             * era chiuso entro il timeout — utile in banco per distinguere
             * subito "che interlock è aperto" senza dover interrogare anche
             * "GET SAB". Stesso dato (SAB_GetInterlockStatus()), stessa
             * causa fisica di SAB_EVT_INTERLOCK_OPEN, solo rilevata in fase
             * di armo (SAB_STATE_ENABLING) anziché dopo (SAB_STATE_ARMED).
             */
            bool a_open, b_open;
            SAB_GetInterlockStatus(&a_open, &b_open);
            SysLog_Event(LOG_ERROR,
                         "SAB: interlock timeout (A:%s B:%s)",
                         a_open ? "OPEN" : "CLOSED",
                         b_open ? "OPEN" : "CLOSED");
            if (g_config.error_mask & ERR_BIT_SAB_TIMEOUT) {
                Queue_PostEvent(SYS_SAB_TIMEOUT_EVENT);
            }
            break;
        }
        case SAB_EVT_INTERLOCK_OPEN: {
            bool a_open, b_open;
            SAB_GetInterlockStatus(&a_open, &b_open);

            if (a_open) {
                SysLog_Event(LOG_ERROR, "SAB: interlock open (channel A)");
                if (g_config.error_mask & ERR_BIT_SAB_INTLCK_A) {
                    Queue_PostEvent(SYS_SAB_INTERLOCK_OPEN_EVENT);
                }
            }
            if (b_open) {
                SysLog_Event(LOG_ERROR, "SAB: interlock open (channel B)");
                if (g_config.error_mask & ERR_BIT_SAB_INTLCK_B) {
                    Queue_PostEvent(SYS_SAB_INTERLOCK_OPEN_EVENT);
                }
            }
            break;
        }
        case SAB_EVT_TEST_FAIL: {
            bool a_fault, b_fault;
            SAB_GetTestStatus(&a_fault, &b_fault);

            if (a_fault) {
                SysLog_Event(LOG_ERROR, "SAB: test signal fault (channel A)");
                if (g_config.error_mask & ERR_BIT_SAB_TEST_A) {
                    Queue_PostEvent(SYS_SAB_TEST_FAIL_EVENT);
                }
            }
            if (b_fault) {
                SysLog_Event(LOG_ERROR, "SAB: test signal fault (channel B)");
                if (g_config.error_mask & ERR_BIT_SAB_TEST_B) {
                    Queue_PostEvent(SYS_SAB_TEST_FAIL_EVENT);
                }
            }
            break;
        }
        default:
            break;
    }
}

/*
 * Sys_HwInit — init hardware che usa HAL blocking (SPI, I2C, ADC, UART, SD).
 *
 * NON chiamare da MX_FREERTOS_Init (pre-scheduler): i timeout HAL (basati su
 * TIM1) non sono affidabili prima di osKernelStart().
 * Viene chiamata come prima istruzione di TaskMonitor_Run (priorità Normal5,
 * la più alta), garantendo che l'HW sia pronto prima che task a priorità
 * inferiore (FSM, Comms, RS485 …) ricevano il loro primo time-slice.
 */
void Sys_HwInit(void)
{
    /*
     * AD7490_Init()/SHT35_Init() NON vengono chiamate qui: richiedono i
     * function pointer wait/signal la cui implementazione (basata su
     * semafori CMSIS-RTOS) è di competenza del layer applicativo, non di
     * questo file di init HW. Vengono chiamate da TaskMonitor_Run() in
     * task_monitor.c, subito dopo Sys_HwInit() — stesso pattern già usato da
     * LaseQ_Init() in task_comms.c.
     */
    EFuse_Init(&hadc1, &hadc3);
    SAB_Init((uint16_t)g_config.sab_interlock_timeout_ms, sab_event_cb);
    AMC_Init(&huart6);      /* USART6 → AMC (STM32G473) */
    /* COM_Interface_Init() NON viene piu' chiamata qui dal 2026-07-17: lo fa
     * TaskComInterface_Init() (MX_FREERTOS_Init(), sotto), che le passa le
     * proprie callback OnMsgPending/OnXferCplt — stesso schema di
     * LaseQ_Init() chiamata da TaskComms_Init(). Nessuna chiamata HAL
     * bloccante in COM_Interface_Init(): sicura anche pre-scheduler. */
    SysLog_Init();          /* Mount FatFS, apre file di log del giorno */
    SysLog_Boot();          /* Prima riga "System boot" */

    /*
     * QCW_Init(): configura TIM16 a livello di registro (non gestito da
     * CubeMX/.ioc — periferica libera, vedi Drivers/QCW/QCW.h). Deve girare
     * DOPO osKernelStart() come gli altri init in Sys_HwInit() (HAL_GetTick()
     * affidabile solo a scheduler avviato); non avvia il timer (QCW_Start()
     * lo fa solo su ingresso in SYS_EMISSION con QCW abilitato).
     */
    QCW_Init();

    /*
     * Watchdog software (heartbeat per task) sopra IWDG1 hardware.
     * Watchdog_LogResetCause() DEVE girare dopo SysLog_Init()/SysLog_Boot()
     * (altrimenti il log è no-op) e legge/cancella i flag RCC PRIMA che
     * qualunque altro reset li sovrascriva — è il primo consumatore di quei
     * flag nel firmware. Watchdog_Init() abilita il refresh condizionato
     * fatto da Watchdog_Service() nel default task (main.c, USER CODE 5).
     */
    Watchdog_LogResetCause();
    Watchdog_Init(&hiwdg1);
}

void MX_FREERTOS_Init(void)
{
    /* Solo init sicuri pre-scheduler: RAM e oggetti RTOS */
    Config_CreateFlashMutex(); /* mutex condiviso settore flash 7 (config.c/lut_manager.c) */
    SPI3Bus_CreateMutex();   /* mutex condiviso SPI3 (SD vs COM interface, vedi SPI3Bus.h) */
    Queues_Init();           /* coda eventi FSM */
    BoardCtrl_Init();        /* GPIO in stato sicuro */
    TaskComms_Init();        /* semafori (safe dopo osKernelInitialize) */
    TaskComInterface_Init(); /* semafori + COM_Interface_Init() (idem) */

    osThreadNew(TaskMonitor_Run,     NULL, &taskMonitor_attr);
    osThreadNew(TaskFSM_Run,         NULL, &taskFSM_attr);
    osThreadNew(TaskComms_Run,       NULL, &taskComms_attr);
    osThreadNew(TaskAmc_Run,         NULL, &taskAmc_attr);
    osThreadNew(TaskComInterface_Run, NULL, &taskComInterface_attr);
    osThreadNew(TaskOutputs_Run,     NULL, &taskOutputs_attr);
    osThreadNew(TaskInputs_Run,      NULL, &taskInputs_attr);
    osThreadNew(Task_RS485,          NULL, &taskRS485_attr);
}

/*
 * @brief  Chiamata da FreeRTOS (vedi configCHECK_FOR_STACK_OVERFLOW in
 *         FreeRTOSConfig.h) quando rileva che lo stack di un task ha
 *         superato il limite allocato. Salva il nome/handle del task in
 *         variabili globali ispezionabili nel debugger e ferma l'esecuzione:
 *         a questo punto lo stack del task è già corrotto, non ha senso
 *         proseguire.
 */
void vApplicationStackOverflowHook(TaskHandle_t xTask, char *pcTaskName)
{
    g_ovfTaskHandle = xTask;
    strncpy((char *)g_ovfTaskName, pcTaskName, configMAX_TASK_NAME_LEN - 1);
    g_ovfTaskName[configMAX_TASK_NAME_LEN - 1] = '\0';

    __asm volatile ("BKPT #02");
    for (;;) { }
}
/* USER CODE END Application */
